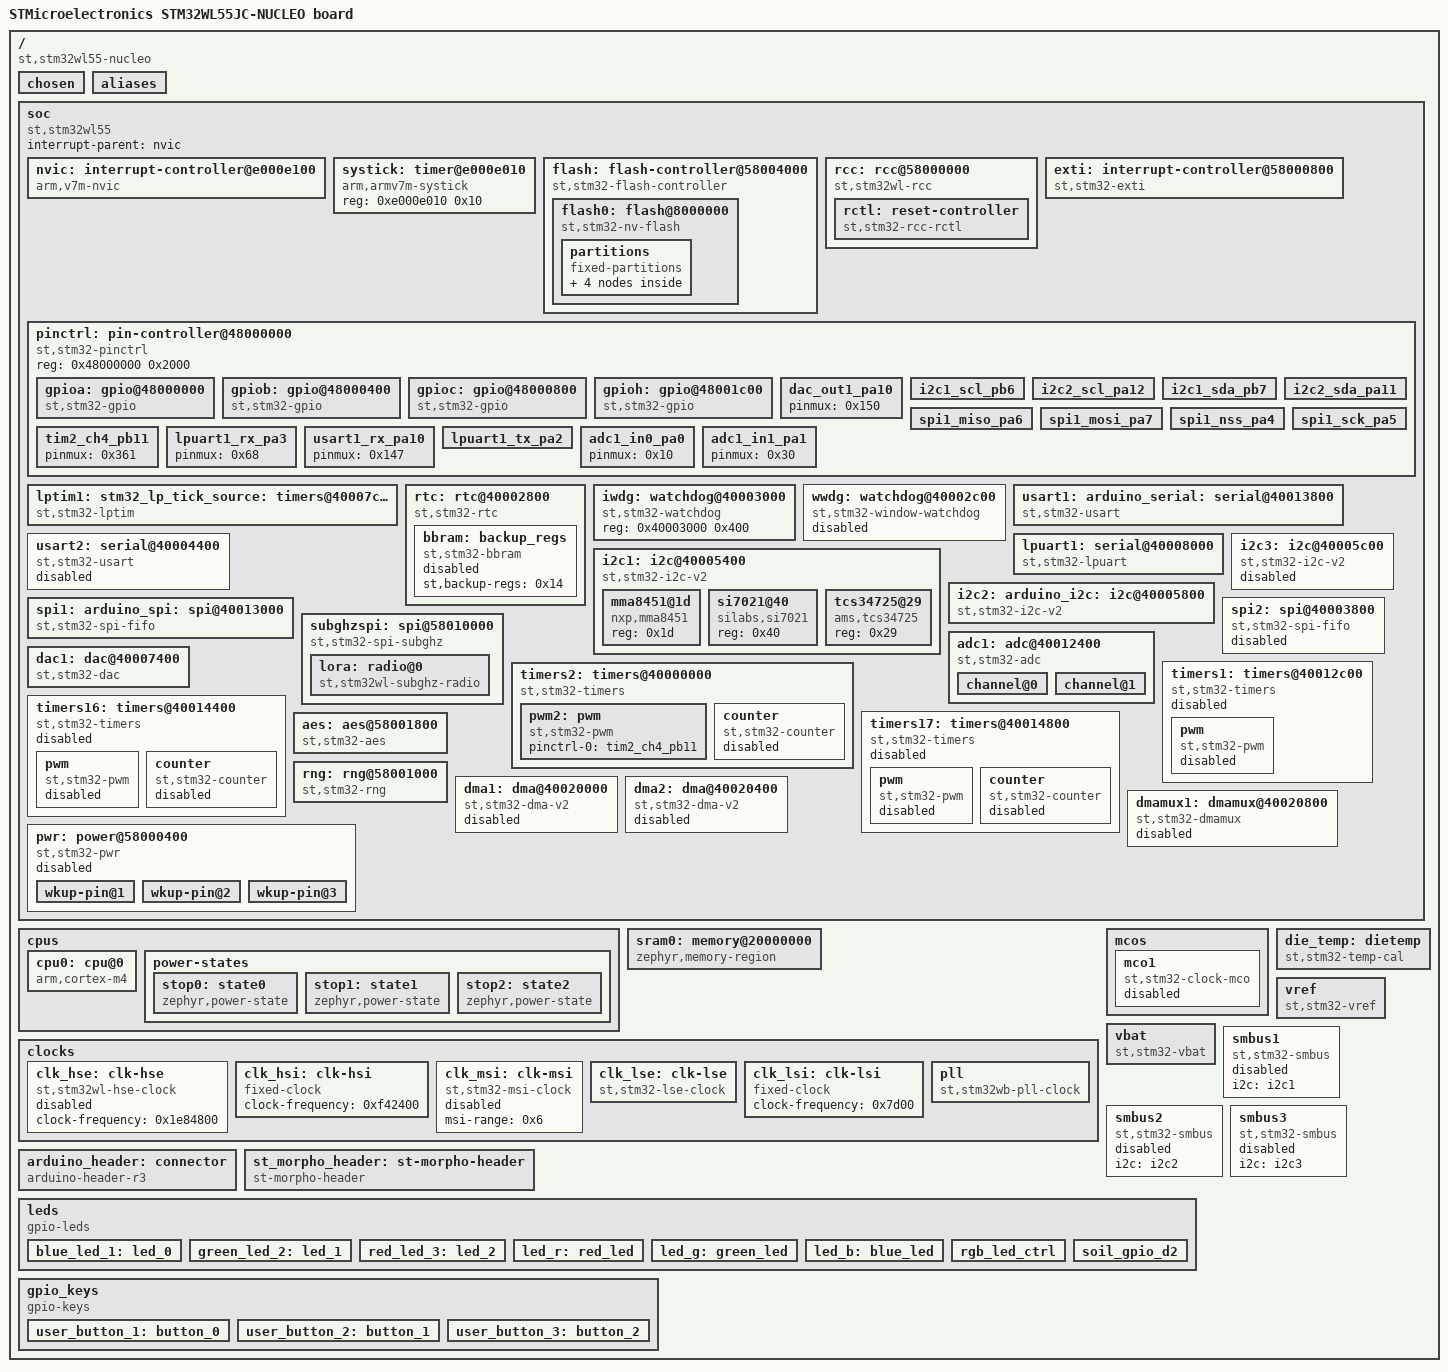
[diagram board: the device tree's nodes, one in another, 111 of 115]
/dts-v1/;

/* node '/' defined in zephyr\dts\common\skeleton.dtsi:9 */
/ {
	#address-cells = < 0x1 >;                              /* in zephyr\dts\common\skeleton.dtsi:10 */
	#size-cells = < 0x1 >;                                 /* in zephyr\dts\common\skeleton.dtsi:11 */
	model = "STMicroelectronics STM32WL55JC-NUCLEO board"; /* in zephyr\boards\st\nucleo_wl55jc\nucleo_wl55jc.dts:15 */
	compatible = "st,stm32wl55-nucleo";                    /* in zephyr\boards\st\nucleo_wl55jc\nucleo_wl55jc.dts:16 */

	/* node '/chosen' defined in zephyr\dts\common\skeleton.dtsi:13 */
	chosen {
		zephyr,entropy = &rng;                    /* in zephyr\dts\arm\st\wl\stm32wl.dtsi:24 */
		zephyr,flash-controller = &flash;         /* in zephyr\dts\arm\st\wl\stm32wl.dtsi:25 */
		zephyr,console = &lpuart1;                /* in zephyr\boards\st\nucleo_wl55jc\nucleo_wl55jc.dts:19 */
		zephyr,shell-uart = &lpuart1;             /* in zephyr\boards\st\nucleo_wl55jc\nucleo_wl55jc.dts:20 */
		zephyr,sram = &sram0;                     /* in zephyr\boards\st\nucleo_wl55jc\nucleo_wl55jc.dts:21 */
		zephyr,flash = &flash0;                   /* in zephyr\boards\st\nucleo_wl55jc\nucleo_wl55jc.dts:22 */
		zephyr,code-partition = &slot0_partition; /* in zephyr\boards\st\nucleo_wl55jc\nucleo_wl55jc.dts:23 */
	};

	/* node '/aliases' defined in zephyr\dts\common\skeleton.dtsi:15 */
	aliases {
		sw1 = &user_button_2;   /* in zephyr\boards\st\nucleo_wl55jc\nucleo_wl55jc.dts:77 */
		sw2 = &user_button_3;   /* in zephyr\boards\st\nucleo_wl55jc\nucleo_wl55jc.dts:78 */
		lora0 = &lora;          /* in zephyr\boards\st\nucleo_wl55jc\nucleo_wl55jc.dts:79 */
		watchdog0 = &iwdg;      /* in zephyr\boards\st\nucleo_wl55jc\nucleo_wl55jc.dts:80 */
		die-temp0 = &die_temp;  /* in zephyr\boards\st\nucleo_wl55jc\nucleo_wl55jc.dts:81 */
		volt-sensor0 = &vref;   /* in zephyr\boards\st\nucleo_wl55jc\nucleo_wl55jc.dts:82 */
		volt-sensor1 = &vbat;   /* in zephyr\boards\st\nucleo_wl55jc\nucleo_wl55jc.dts:83 */
		analogin0 = &adc1;      /* in ..\Downloads\blink_basic\build\zephyr\boards\nucleo_wl55jc.overlay:3 */
		led0 = &led_r;          /* in ..\Downloads\blink_basic\build\zephyr\boards\nucleo_wl55jc.overlay:4 */
		led1 = &led_g;          /* in ..\Downloads\blink_basic\build\zephyr\boards\nucleo_wl55jc.overlay:5 */
		led2 = &led_b;          /* in ..\Downloads\blink_basic\build\zephyr\boards\nucleo_wl55jc.overlay:6 */
		sw0 = &user_button_3;   /* in ..\Downloads\blink_basic\build\zephyr\boards\nucleo_wl55jc.overlay:7 */
		rgbled = &rgb_led_ctrl; /* in ..\Downloads\blink_basic\build\zephyr\boards\nucleo_wl55jc.overlay:8 */
		soil = &soil_gpio_d2;   /* in ..\Downloads\blink_basic\build\zephyr\boards\nucleo_wl55jc.overlay:9 */
	};

	/* node '/soc' defined in zephyr\dts\arm\armv7-m.dtsi:6 */
	soc {
		#address-cells = < 0x1 >;     /* in zephyr\dts\arm\armv7-m.dtsi:7 */
		#size-cells = < 0x1 >;        /* in zephyr\dts\arm\armv7-m.dtsi:8 */
		interrupt-parent = < &nvic >; /* in zephyr\dts\arm\armv7-m.dtsi:10 */
		ranges;                       /* in zephyr\dts\arm\armv7-m.dtsi:11 */
		compatible = "st,stm32wl55",
		             "st,stm32wl",
		             "simple-bus";    /* in zephyr\dts\arm\st\wl\stm32wl55.dtsi:11 */

		/* node '/soc/interrupt-controller@e000e100' defined in zephyr\dts\arm\armv7-m.dtsi:13 */
		nvic: interrupt-controller@e000e100 {
			#address-cells = < 0x1 >;            /* in zephyr\dts\arm\armv7-m.dtsi:14 */
			compatible = "arm,v7m-nvic";         /* in zephyr\dts\arm\armv7-m.dtsi:15 */
			reg = < 0xe000e100 0xc00 >;          /* in zephyr\dts\arm\armv7-m.dtsi:16 */
			interrupt-controller;                /* in zephyr\dts\arm\armv7-m.dtsi:17 */
			#interrupt-cells = < 0x2 >;          /* in zephyr\dts\arm\armv7-m.dtsi:18 */
			arm,num-irq-priority-bits = < 0x4 >; /* in zephyr\dts\arm\st\wl\stm32wl.dtsi:604 */
			phandle = < 0x1 >;                   /* in zephyr\dts\arm\armv7-m.dtsi:10 */
		};

		/* node '/soc/timer@e000e010' defined in zephyr\dts\arm\armv7-m.dtsi:21 */
		systick: timer@e000e010 {
			compatible = "arm,armv7m-systick"; /* in zephyr\dts\arm\armv7-m.dtsi:22 */
			reg = < 0xe000e010 0x10 >;         /* in zephyr\dts\arm\armv7-m.dtsi:23 */
		};

		/* node '/soc/flash-controller@58004000' defined in zephyr\dts\arm\st\wl\stm32wl.dtsi:121 */
		flash: flash-controller@58004000 {
			compatible = "st,stm32-flash-controller",
			             "st,stm32l4-flash-controller"; /* in zephyr\dts\arm\st\wl\stm32wl.dtsi:122 */
			reg = < 0x58004000 0x400 >;                 /* in zephyr\dts\arm\st\wl\stm32wl.dtsi:123 */
			interrupts = < 0x4 0x0 >;                   /* in zephyr\dts\arm\st\wl\stm32wl.dtsi:124 */
			#address-cells = < 0x1 >;                   /* in zephyr\dts\arm\st\wl\stm32wl.dtsi:126 */
			#size-cells = < 0x1 >;                      /* in zephyr\dts\arm\st\wl\stm32wl.dtsi:127 */

			/* node '/soc/flash-controller@58004000/flash@8000000' defined in zephyr\dts\arm\st\wl\stm32wl.dtsi:129 */
			flash0: flash@8000000 {
				compatible = "st,stm32-nv-flash",
				             "soc-nv-flash";      /* in zephyr\dts\arm\st\wl\stm32wl.dtsi:130 */
				write-block-size = < 0x8 >;       /* in zephyr\dts\arm\st\wl\stm32wl.dtsi:132 */
				erase-block-size = < 0x800 >;     /* in zephyr\dts\arm\st\wl\stm32wl.dtsi:133 */
				max-erase-time = < 0x19 >;        /* in zephyr\dts\arm\st\wl\stm32wl.dtsi:135 */
				reg = < 0x8000000 0x40000 >;      /* in zephyr\dts\arm\st\wl\stm32wl55Xc.dtsi:16 */

				/* node '/soc/flash-controller@58004000/flash@8000000/partitions' defined in zephyr\boards\st\nucleo_wl55jc\nucleo_wl55jc.dts:209 */
				partitions {
					compatible = "fixed-partitions"; /* in zephyr\boards\st\nucleo_wl55jc\nucleo_wl55jc.dts:210 */
					#address-cells = < 0x1 >;        /* in zephyr\boards\st\nucleo_wl55jc\nucleo_wl55jc.dts:211 */
					#size-cells = < 0x1 >;           /* in zephyr\boards\st\nucleo_wl55jc\nucleo_wl55jc.dts:212 */

					/* node '/soc/flash-controller@58004000/flash@8000000/partitions/partition@0' defined in zephyr\boards\st\nucleo_wl55jc\nucleo_wl55jc.dts:215 */
					boot_partition: partition@0 {
						label = "mcuboot";    /* in zephyr\boards\st\nucleo_wl55jc\nucleo_wl55jc.dts:216 */
						reg = < 0x0 0x8000 >; /* in zephyr\boards\st\nucleo_wl55jc\nucleo_wl55jc.dts:217 */
						read-only;            /* in zephyr\boards\st\nucleo_wl55jc\nucleo_wl55jc.dts:218 */
					};

					/* node '/soc/flash-controller@58004000/flash@8000000/partitions/partition@8000' defined in zephyr\boards\st\nucleo_wl55jc\nucleo_wl55jc.dts:222 */
					slot0_partition: partition@8000 {
						label = "image-0";        /* in zephyr\boards\st\nucleo_wl55jc\nucleo_wl55jc.dts:223 */
						reg = < 0x8000 0x1a000 >; /* in zephyr\boards\st\nucleo_wl55jc\nucleo_wl55jc.dts:224 */
					};

					/* node '/soc/flash-controller@58004000/flash@8000000/partitions/partition@22000' defined in zephyr\boards\st\nucleo_wl55jc\nucleo_wl55jc.dts:228 */
					slot1_partition: partition@22000 {
						label = "image-1";         /* in zephyr\boards\st\nucleo_wl55jc\nucleo_wl55jc.dts:229 */
						reg = < 0x22000 0x1a000 >; /* in zephyr\boards\st\nucleo_wl55jc\nucleo_wl55jc.dts:230 */
					};

					/* node '/soc/flash-controller@58004000/flash@8000000/partitions/partition@3c000' defined in zephyr\boards\st\nucleo_wl55jc\nucleo_wl55jc.dts:238 */
					storage_partition: partition@3c000 {
						label = "storage";        /* in zephyr\boards\st\nucleo_wl55jc\nucleo_wl55jc.dts:239 */
						reg = < 0x3c000 0x4000 >; /* in zephyr\boards\st\nucleo_wl55jc\nucleo_wl55jc.dts:240 */
					};
				};
			};
		};

		/* node '/soc/rcc@58000000' defined in zephyr\dts\arm\st\wl\stm32wl.dtsi:139 */
		rcc: rcc@58000000 {
			compatible = "st,stm32wl-rcc";   /* in zephyr\dts\arm\st\wl\stm32wl.dtsi:140 */
			#clock-cells = < 0x2 >;          /* in zephyr\dts\arm\st\wl\stm32wl.dtsi:141 */
			reg = < 0x58000000 0x400 >;      /* in zephyr\dts\arm\st\wl\stm32wl.dtsi:142 */
			clocks = < &pll >;               /* in zephyr\boards\st\nucleo_wl55jc\nucleo_wl55jc.dts:116 */
			clock-frequency = < 0x2dc6c00 >; /* in zephyr\boards\st\nucleo_wl55jc\nucleo_wl55jc.dts:117 */
			cpu1-prescaler = < 0x1 >;        /* in zephyr\boards\st\nucleo_wl55jc\nucleo_wl55jc.dts:118 */
			cpu2-prescaler = < 0x1 >;        /* in zephyr\boards\st\nucleo_wl55jc\nucleo_wl55jc.dts:119 */
			ahb3-prescaler = < 0x1 >;        /* in zephyr\boards\st\nucleo_wl55jc\nucleo_wl55jc.dts:120 */
			apb1-prescaler = < 0x1 >;        /* in zephyr\boards\st\nucleo_wl55jc\nucleo_wl55jc.dts:121 */
			apb2-prescaler = < 0x1 >;        /* in zephyr\boards\st\nucleo_wl55jc\nucleo_wl55jc.dts:122 */
			phandle = < 0x3 >;               /* in zephyr\dts\arm\st\wl\stm32wl.dtsi:156 */

			/* node '/soc/rcc@58000000/reset-controller' defined in zephyr\dts\arm\st\wl\stm32wl.dtsi:144 */
			rctl: reset-controller {
				compatible = "st,stm32-rcc-rctl"; /* in zephyr\dts\arm\st\wl\stm32wl.dtsi:145 */
				#reset-cells = < 0x1 >;           /* in zephyr\dts\arm\st\wl\stm32wl.dtsi:146 */
				phandle = < 0x4 >;                /* in zephyr\dts\arm\st\wl\stm32wl.dtsi:257 */
			};
		};

		/* node '/soc/interrupt-controller@58000800' defined in zephyr\dts\arm\st\wl\stm32wl.dtsi:150 */
		exti: interrupt-controller@58000800 {
			compatible = "st,stm32-exti";  /* in zephyr\dts\arm\st\wl\stm32wl.dtsi:151 */
			interrupt-controller;          /* in zephyr\dts\arm\st\wl\stm32wl.dtsi:152 */
			#interrupt-cells = < 0x1 >;    /* in zephyr\dts\arm\st\wl\stm32wl.dtsi:153 */
			#address-cells = < 0x0 >;      /* in zephyr\dts\arm\st\wl\stm32wl.dtsi:154 */
			reg = < 0x58000800 0x400 >;    /* in zephyr\dts\arm\st\wl\stm32wl.dtsi:155 */
			clocks = < &rcc 0x54 0x100 >;  /* in zephyr\dts\arm\st\wl\stm32wl.dtsi:156 */
			num-lines = < 0x40 >;          /* in zephyr\dts\arm\st\wl\stm32wl.dtsi:157 */
			interrupts = < 0x6 0x0 >,
			             < 0x7 0x0 >,
			             < 0x8 0x0 >,
			             < 0x9 0x0 >,
			             < 0xa 0x0 >,
			             < 0x16 0x0 >,
			             < 0x29 0x0 >;     /* in zephyr\dts\arm\st\wl\stm32wl.dtsi:158 */
			interrupt-names = "line0",
			                  "line1",
			                  "line2",
			                  "line3",
			                  "line4",
			                  "line5-9",
			                  "line10-15"; /* in zephyr\dts\arm\st\wl\stm32wl.dtsi:160 */
			line-ranges = < 0x0 0x1 >,
			              < 0x1 0x1 >,
			              < 0x2 0x1 >,
			              < 0x3 0x1 >,
			              < 0x4 0x1 >,
			              < 0x5 0x5 >,
			              < 0xa 0x6 >;     /* in zephyr\dts\arm\st\wl\stm32wl.dtsi:162 */
		};

		/* node '/soc/pin-controller@48000000' defined in zephyr\dts\arm\st\wl\stm32wl.dtsi:166 */
		pinctrl: pin-controller@48000000 {
			compatible = "st,stm32-pinctrl"; /* in zephyr\dts\arm\st\wl\stm32wl.dtsi:167 */
			#address-cells = < 0x1 >;        /* in zephyr\dts\arm\st\wl\stm32wl.dtsi:168 */
			#size-cells = < 0x1 >;           /* in zephyr\dts\arm\st\wl\stm32wl.dtsi:169 */
			reg = < 0x48000000 0x2000 >;     /* in zephyr\dts\arm\st\wl\stm32wl.dtsi:170 */

			/* node '/soc/pin-controller@48000000/gpio@48000000' defined in zephyr\dts\arm\st\wl\stm32wl.dtsi:172 */
			gpioa: gpio@48000000 {
				compatible = "st,stm32-gpio"; /* in zephyr\dts\arm\st\wl\stm32wl.dtsi:173 */
				gpio-controller;              /* in zephyr\dts\arm\st\wl\stm32wl.dtsi:174 */
				#gpio-cells = < 0x2 >;        /* in zephyr\dts\arm\st\wl\stm32wl.dtsi:175 */
				reg = < 0x48000000 0x400 >;   /* in zephyr\dts\arm\st\wl\stm32wl.dtsi:176 */
				clocks = < &rcc 0x4c 0x1 >;   /* in zephyr\dts\arm\st\wl\stm32wl.dtsi:177 */
				phandle = < 0x15 >;           /* in zephyr\dts\arm\st\wl\stm32wl.dtsi:537 */
			};

			/* node '/soc/pin-controller@48000000/gpio@48000400' defined in zephyr\dts\arm\st\wl\stm32wl.dtsi:180 */
			gpiob: gpio@48000400 {
				compatible = "st,stm32-gpio"; /* in zephyr\dts\arm\st\wl\stm32wl.dtsi:181 */
				gpio-controller;              /* in zephyr\dts\arm\st\wl\stm32wl.dtsi:182 */
				#gpio-cells = < 0x2 >;        /* in zephyr\dts\arm\st\wl\stm32wl.dtsi:183 */
				reg = < 0x48000400 0x400 >;   /* in zephyr\dts\arm\st\wl\stm32wl.dtsi:184 */
				clocks = < &rcc 0x4c 0x2 >;   /* in zephyr\dts\arm\st\wl\stm32wl.dtsi:185 */
				phandle = < 0x16 >;           /* in zephyr\dts\arm\st\wl\stm32wl.dtsi:547 */
			};

			/* node '/soc/pin-controller@48000000/gpio@48000800' defined in zephyr\dts\arm\st\wl\stm32wl.dtsi:188 */
			gpioc: gpio@48000800 {
				compatible = "st,stm32-gpio"; /* in zephyr\dts\arm\st\wl\stm32wl.dtsi:189 */
				gpio-controller;              /* in zephyr\dts\arm\st\wl\stm32wl.dtsi:190 */
				#gpio-cells = < 0x2 >;        /* in zephyr\dts\arm\st\wl\stm32wl.dtsi:191 */
				reg = < 0x48000800 0x400 >;   /* in zephyr\dts\arm\st\wl\stm32wl.dtsi:192 */
				clocks = < &rcc 0x4c 0x4 >;   /* in zephyr\dts\arm\st\wl\stm32wl.dtsi:193 */
				phandle = < 0x10 >;           /* in zephyr\boards\st\nucleo_wl55jc\nucleo_wl55jc.dts:193 */
			};

			/* node '/soc/pin-controller@48000000/gpio@48001c00' defined in zephyr\dts\arm\st\wl\stm32wl.dtsi:196 */
			gpioh: gpio@48001c00 {
				compatible = "st,stm32-gpio"; /* in zephyr\dts\arm\st\wl\stm32wl.dtsi:197 */
				gpio-controller;              /* in zephyr\dts\arm\st\wl\stm32wl.dtsi:198 */
				#gpio-cells = < 0x2 >;        /* in zephyr\dts\arm\st\wl\stm32wl.dtsi:199 */
				reg = < 0x48001c00 0x400 >;   /* in zephyr\dts\arm\st\wl\stm32wl.dtsi:200 */
				clocks = < &rcc 0x4c 0x80 >;  /* in zephyr\dts\arm\st\wl\stm32wl.dtsi:201 */
				phandle = < 0x1f >;           /* in zephyr\boards\st\nucleo_wl55jc\st_morpho_connector.dtsi:15 */
			};

			/* node '/soc/pin-controller@48000000/dac_out1_pa10' defined in modules\hal\stm32\dts\st\wl\stm32wl55jcix-pinctrl.dtsi:323 */
			dac_out1_pa10: dac_out1_pa10 {
				pinmux = < 0x150 >; /* in modules\hal\stm32\dts\st\wl\stm32wl55jcix-pinctrl.dtsi:324 */
				phandle = < 0x13 >; /* in zephyr\boards\st\nucleo_wl55jc\nucleo_wl55jc.dts:147 */
			};

			/* node '/soc/pin-controller@48000000/i2c1_scl_pb6' defined in modules\hal\stm32\dts\st\wl\stm32wl55jcix-pinctrl.dtsi:335 */
			i2c1_scl_pb6: i2c1_scl_pb6 {
				pinmux = < 0x2c4 >; /* in modules\hal\stm32\dts\st\wl\stm32wl55jcix-pinctrl.dtsi:336 */
				bias-pull-up;       /* in modules\hal\stm32\dts\st\wl\stm32wl55jcix-pinctrl.dtsi:337 */
				drive-open-drain;   /* in modules\hal\stm32\dts\st\wl\stm32wl55jcix-pinctrl.dtsi:338 */
				phandle = < 0x8 >;  /* in ..\Downloads\blink_basic\build\zephyr\boards\nucleo_wl55jc.overlay:69 */
			};

			/* node '/soc/pin-controller@48000000/i2c2_scl_pa12' defined in modules\hal\stm32\dts\st\wl\stm32wl55jcix-pinctrl.dtsi:347 */
			i2c2_scl_pa12: i2c2_scl_pa12 {
				pinmux = < 0x184 >; /* in modules\hal\stm32\dts\st\wl\stm32wl55jcix-pinctrl.dtsi:348 */
				bias-pull-up;       /* in modules\hal\stm32\dts\st\wl\stm32wl55jcix-pinctrl.dtsi:349 */
				drive-open-drain;   /* in modules\hal\stm32\dts\st\wl\stm32wl55jcix-pinctrl.dtsi:350 */
				phandle = < 0xa >;  /* in zephyr\boards\st\nucleo_wl55jc\nucleo_wl55jc.dts:133 */
			};

			/* node '/soc/pin-controller@48000000/i2c1_sda_pb7' defined in modules\hal\stm32\dts\st\wl\stm32wl55jcix-pinctrl.dtsi:391 */
			i2c1_sda_pb7: i2c1_sda_pb7 {
				pinmux = < 0x2e4 >; /* in modules\hal\stm32\dts\st\wl\stm32wl55jcix-pinctrl.dtsi:392 */
				bias-pull-up;       /* in modules\hal\stm32\dts\st\wl\stm32wl55jcix-pinctrl.dtsi:393 */
				drive-open-drain;   /* in modules\hal\stm32\dts\st\wl\stm32wl55jcix-pinctrl.dtsi:394 */
				phandle = < 0x9 >;  /* in ..\Downloads\blink_basic\build\zephyr\boards\nucleo_wl55jc.overlay:69 */
			};

			/* node '/soc/pin-controller@48000000/i2c2_sda_pa11' defined in modules\hal\stm32\dts\st\wl\stm32wl55jcix-pinctrl.dtsi:403 */
			i2c2_sda_pa11: i2c2_sda_pa11 {
				pinmux = < 0x164 >; /* in modules\hal\stm32\dts\st\wl\stm32wl55jcix-pinctrl.dtsi:404 */
				bias-pull-up;       /* in modules\hal\stm32\dts\st\wl\stm32wl55jcix-pinctrl.dtsi:405 */
				drive-open-drain;   /* in modules\hal\stm32\dts\st\wl\stm32wl55jcix-pinctrl.dtsi:406 */
				phandle = < 0xb >;  /* in zephyr\boards\st\nucleo_wl55jc\nucleo_wl55jc.dts:133 */
			};

			/* node '/soc/pin-controller@48000000/spi1_miso_pa6' defined in modules\hal\stm32\dts\st\wl\stm32wl55jcix-pinctrl.dtsi:583 */
			spi1_miso_pa6: spi1_miso_pa6 {
				pinmux = < 0xc5 >; /* in modules\hal\stm32\dts\st\wl\stm32wl55jcix-pinctrl.dtsi:584 */
				bias-pull-down;    /* in modules\hal\stm32\dts\st\wl\stm32wl55jcix-pinctrl.dtsi:585 */
				phandle = < 0xe >; /* in zephyr\boards\st\nucleo_wl55jc\nucleo_wl55jc.dts:140 */
			};

			/* node '/soc/pin-controller@48000000/spi1_mosi_pa7' defined in modules\hal\stm32\dts\st\wl\stm32wl55jcix-pinctrl.dtsi:615 */
			spi1_mosi_pa7: spi1_mosi_pa7 {
				pinmux = < 0xe5 >; /* in modules\hal\stm32\dts\st\wl\stm32wl55jcix-pinctrl.dtsi:616 */
				bias-pull-down;    /* in modules\hal\stm32\dts\st\wl\stm32wl55jcix-pinctrl.dtsi:617 */
				phandle = < 0xf >; /* in zephyr\boards\st\nucleo_wl55jc\nucleo_wl55jc.dts:140 */
			};

			/* node '/soc/pin-controller@48000000/spi1_nss_pa4' defined in modules\hal\stm32\dts\st\wl\stm32wl55jcix-pinctrl.dtsi:652 */
			spi1_nss_pa4: spi1_nss_pa4 {
				pinmux = < 0x85 >; /* in modules\hal\stm32\dts\st\wl\stm32wl55jcix-pinctrl.dtsi:653 */
				bias-pull-up;      /* in modules\hal\stm32\dts\st\wl\stm32wl55jcix-pinctrl.dtsi:654 */
				phandle = < 0xc >; /* in zephyr\boards\st\nucleo_wl55jc\nucleo_wl55jc.dts:140 */
			};

			/* node '/soc/pin-controller@48000000/spi1_sck_pa5' defined in modules\hal\stm32\dts\st\wl\stm32wl55jcix-pinctrl.dtsi:690 */
			spi1_sck_pa5: spi1_sck_pa5 {
				pinmux = < 0xa5 >;             /* in modules\hal\stm32\dts\st\wl\stm32wl55jcix-pinctrl.dtsi:691 */
				bias-pull-down;                /* in modules\hal\stm32\dts\st\wl\stm32wl55jcix-pinctrl.dtsi:692 */
				slew-rate = "very-high-speed"; /* in modules\hal\stm32\dts\st\wl\stm32wl55jcix-pinctrl.dtsi:693 */
				phandle = < 0xd >;             /* in zephyr\boards\st\nucleo_wl55jc\nucleo_wl55jc.dts:140 */
			};

			/* node '/soc/pin-controller@48000000/tim2_ch4_pb11' defined in modules\hal\stm32\dts\st\wl\stm32wl55jcix-pinctrl.dtsi:830 */
			tim2_ch4_pb11: tim2_ch4_pb11 {
				pinmux = < 0x361 >; /* in modules\hal\stm32\dts\st\wl\stm32wl55jcix-pinctrl.dtsi:831 */
				phandle = < 0x14 >; /* in zephyr\boards\st\nucleo_wl55jc\nucleo_wl55jc.dts:158 */
			};

			/* node '/soc/pin-controller@48000000/lpuart1_rx_pa3' defined in modules\hal\stm32\dts\st\wl\stm32wl55jcix-pinctrl.dtsi:941 */
			lpuart1_rx_pa3: lpuart1_rx_pa3 {
				pinmux = < 0x68 >; /* in modules\hal\stm32\dts\st\wl\stm32wl55jcix-pinctrl.dtsi:942 */
				phandle = < 0x7 >; /* in zephyr\boards\st\nucleo_wl55jc\nucleo_wl55jc.dts:126 */
			};

			/* node '/soc/pin-controller@48000000/usart1_rx_pa10' defined in modules\hal\stm32\dts\st\wl\stm32wl55jcix-pinctrl.dtsi:945 */
			usart1_rx_pa10: usart1_rx_pa10 {
				pinmux = < 0x147 >; /* in modules\hal\stm32\dts\st\wl\stm32wl55jcix-pinctrl.dtsi:946 */
				phandle = < 0x5 >;  /* in ..\Downloads\blink_basic\build\zephyr\boards\nucleo_wl55jc.overlay:111 */
			};

			/* node '/soc/pin-controller@48000000/lpuart1_tx_pa2' defined in modules\hal\stm32\dts\st\wl\stm32wl55jcix-pinctrl.dtsi:967 */
			lpuart1_tx_pa2: lpuart1_tx_pa2 {
				pinmux = < 0x48 >; /* in modules\hal\stm32\dts\st\wl\stm32wl55jcix-pinctrl.dtsi:968 */
				bias-pull-up;      /* in modules\hal\stm32\dts\st\wl\stm32wl55jcix-pinctrl.dtsi:969 */
				phandle = < 0x6 >; /* in zephyr\boards\st\nucleo_wl55jc\nucleo_wl55jc.dts:126 */
			};

			/* node '/soc/pin-controller@48000000/adc1_in0_pa0' defined in ..\Downloads\blink_basic\build\zephyr\boards\nucleo_wl55jc.overlay:100 */
			adc1_in0_pa0: adc1_in0_pa0 {
				pinmux = < 0x10 >;  /* in ..\Downloads\blink_basic\build\zephyr\boards\nucleo_wl55jc.overlay:101 */
				phandle = < 0x11 >; /* in ..\Downloads\blink_basic\build\zephyr\boards\nucleo_wl55jc.overlay:44 */
			};

			/* node '/soc/pin-controller@48000000/adc1_in1_pa1' defined in ..\Downloads\blink_basic\build\zephyr\boards\nucleo_wl55jc.overlay:103 */
			adc1_in1_pa1: adc1_in1_pa1 {
				pinmux = < 0x30 >;  /* in ..\Downloads\blink_basic\build\zephyr\boards\nucleo_wl55jc.overlay:104 */
				phandle = < 0x12 >; /* in ..\Downloads\blink_basic\build\zephyr\boards\nucleo_wl55jc.overlay:44 */
			};
		};

		/* node '/soc/timers@40007c00' defined in zephyr\dts\arm\st\wl\stm32wl.dtsi:205 */
		lptim1: stm32_lp_tick_source: timers@40007c00 {
			compatible = "st,stm32-lptim";     /* in zephyr\dts\arm\st\wl\stm32wl.dtsi:206 */
			#address-cells = < 0x1 >;          /* in zephyr\dts\arm\st\wl\stm32wl.dtsi:208 */
			#size-cells = < 0x0 >;             /* in zephyr\dts\arm\st\wl\stm32wl.dtsi:209 */
			reg = < 0x40007c00 0x400 >;        /* in zephyr\dts\arm\st\wl\stm32wl.dtsi:210 */
			interrupts = < 0x27 0x1 >;         /* in zephyr\dts\arm\st\wl\stm32wl.dtsi:211 */
			interrupt-names = "wakeup";        /* in zephyr\dts\arm\st\wl\stm32wl.dtsi:212 */
			clocks = < &rcc 0x58 0x80000000 >,
			         < &rcc 0x3 0x1320088 >;   /* in zephyr\boards\st\nucleo_wl55jc\nucleo_wl55jc.dts:93 */
			status = "okay";                   /* in zephyr\boards\st\nucleo_wl55jc\nucleo_wl55jc.dts:95 */
		};

		/* node '/soc/rtc@40002800' defined in zephyr\dts\arm\st\wl\stm32wl.dtsi:216 */
		rtc: rtc@40002800 {
			compatible = "st,stm32-rtc";     /* in zephyr\dts\arm\st\wl\stm32wl.dtsi:217 */
			reg = < 0x40002800 0x400 >;      /* in zephyr\dts\arm\st\wl\stm32wl.dtsi:218 */
			interrupts = < 0x2a 0x0 >;       /* in zephyr\dts\arm\st\wl\stm32wl.dtsi:219 */
			prescaler = < 0x8000 >;          /* in zephyr\dts\arm\st\wl\stm32wl.dtsi:221 */
			alarms-count = < 0x2 >;          /* in zephyr\dts\arm\st\wl\stm32wl.dtsi:222 */
			alrm-exti-line = < 0x11 >;       /* in zephyr\dts\arm\st\wl\stm32wl.dtsi:223 */
			clocks = < &rcc 0x58 0x400 >,
			         < &rcc 0x2 0x1280090 >; /* in zephyr\boards\st\nucleo_wl55jc\nucleo_wl55jc.dts:246 */
			status = "okay";                 /* in zephyr\boards\st\nucleo_wl55jc\nucleo_wl55jc.dts:248 */

			/* node '/soc/rtc@40002800/backup_regs' defined in zephyr\dts\arm\st\wl\stm32wl.dtsi:232 */
			bbram: backup_regs {
				compatible = "st,stm32-bbram"; /* in zephyr\dts\arm\st\wl\stm32wl.dtsi:233 */
				st,backup-regs = < 0x14 >;     /* in zephyr\dts\arm\st\wl\stm32wl.dtsi:234 */
				status = "disabled";           /* in zephyr\dts\arm\st\wl\stm32wl.dtsi:235 */
			};
		};

		/* node '/soc/watchdog@40003000' defined in zephyr\dts\arm\st\wl\stm32wl.dtsi:239 */
		iwdg: watchdog@40003000 {
			compatible = "st,stm32-watchdog"; /* in zephyr\dts\arm\st\wl\stm32wl.dtsi:240 */
			reg = < 0x40003000 0x400 >;       /* in zephyr\dts\arm\st\wl\stm32wl.dtsi:241 */
			status = "okay";                  /* in zephyr\boards\st\nucleo_wl55jc\nucleo_wl55jc.dts:184 */
		};

		/* node '/soc/watchdog@40002c00' defined in zephyr\dts\arm\st\wl\stm32wl.dtsi:245 */
		wwdg: watchdog@40002c00 {
			compatible = "st,stm32-window-watchdog"; /* in zephyr\dts\arm\st\wl\stm32wl.dtsi:246 */
			reg = < 0x40002c00 0x400 >;              /* in zephyr\dts\arm\st\wl\stm32wl.dtsi:247 */
			clocks = < &rcc 0x58 0x800 >;            /* in zephyr\dts\arm\st\wl\stm32wl.dtsi:248 */
			interrupts = < 0x0 0x7 >;                /* in zephyr\dts\arm\st\wl\stm32wl.dtsi:249 */
			status = "disabled";                     /* in zephyr\dts\arm\st\wl\stm32wl.dtsi:250 */
		};

		/* node '/soc/serial@40013800' defined in zephyr\dts\arm\st\wl\stm32wl.dtsi:253 */
		usart1: arduino_serial: serial@40013800 {
			compatible = "st,stm32-usart",
			             "st,stm32-uart";    /* in zephyr\dts\arm\st\wl\stm32wl.dtsi:254 */
			reg = < 0x40013800 0x400 >;      /* in zephyr\dts\arm\st\wl\stm32wl.dtsi:255 */
			clocks = < &rcc 0x60 0x4000 >;   /* in zephyr\dts\arm\st\wl\stm32wl.dtsi:256 */
			resets = < &rctl 0x80e >;        /* in zephyr\dts\arm\st\wl\stm32wl.dtsi:257 */
			interrupts = < 0x24 0x0 >;       /* in zephyr\dts\arm\st\wl\stm32wl.dtsi:258 */
			status = "okay";                 /* in ..\Downloads\blink_basic\build\zephyr\boards\nucleo_wl55jc.overlay:109 */
			current-speed = < 0x2580 >;      /* in ..\Downloads\blink_basic\build\zephyr\boards\nucleo_wl55jc.overlay:110 */
			pinctrl-0 = < &usart1_rx_pa10 >; /* in ..\Downloads\blink_basic\build\zephyr\boards\nucleo_wl55jc.overlay:111 */
			pinctrl-names = "default";       /* in ..\Downloads\blink_basic\build\zephyr\boards\nucleo_wl55jc.overlay:112 */
		};

		/* node '/soc/serial@40004400' defined in zephyr\dts\arm\st\wl\stm32wl.dtsi:262 */
		usart2: serial@40004400 {
			compatible = "st,stm32-usart",
			             "st,stm32-uart";   /* in zephyr\dts\arm\st\wl\stm32wl.dtsi:263 */
			reg = < 0x40004400 0x400 >;     /* in zephyr\dts\arm\st\wl\stm32wl.dtsi:264 */
			clocks = < &rcc 0x58 0x20000 >; /* in zephyr\dts\arm\st\wl\stm32wl.dtsi:265 */
			resets = < &rctl 0x711 >;       /* in zephyr\dts\arm\st\wl\stm32wl.dtsi:266 */
			interrupts = < 0x25 0x0 >;      /* in zephyr\dts\arm\st\wl\stm32wl.dtsi:267 */
			status = "disabled";            /* in zephyr\dts\arm\st\wl\stm32wl.dtsi:268 */
		};

		/* node '/soc/serial@40008000' defined in zephyr\dts\arm\st\wl\stm32wl.dtsi:271 */
		lpuart1: serial@40008000 {
			compatible = "st,stm32-lpuart",
			             "st,stm32-uart";                    /* in zephyr\dts\arm\st\wl\stm32wl.dtsi:272 */
			reg = < 0x40008000 0x400 >;                      /* in zephyr\dts\arm\st\wl\stm32wl.dtsi:273 */
			clocks = < &rcc 0x5c 0x1 >;                      /* in zephyr\dts\arm\st\wl\stm32wl.dtsi:274 */
			resets = < &rctl 0x780 >;                        /* in zephyr\dts\arm\st\wl\stm32wl.dtsi:275 */
			interrupts = < 0x26 0x0 >;                       /* in zephyr\dts\arm\st\wl\stm32wl.dtsi:276 */
			wakeup-line = < 0x1c >;                          /* in zephyr\dts\arm\st\wl\stm32wl.dtsi:277 */
			pinctrl-0 = < &lpuart1_tx_pa2 &lpuart1_rx_pa3 >; /* in zephyr\boards\st\nucleo_wl55jc\nucleo_wl55jc.dts:126 */
			pinctrl-names = "default";                       /* in zephyr\boards\st\nucleo_wl55jc\nucleo_wl55jc.dts:127 */
			current-speed = < 0x1c200 >;                     /* in zephyr\boards\st\nucleo_wl55jc\nucleo_wl55jc.dts:128 */
			status = "okay";                                 /* in zephyr\boards\st\nucleo_wl55jc\nucleo_wl55jc.dts:129 */
		};

		/* node '/soc/i2c@40005400' defined in zephyr\dts\arm\st\wl\stm32wl.dtsi:281 */
		i2c1: i2c@40005400 {
			compatible = "st,stm32-i2c-v2";              /* in zephyr\dts\arm\st\wl\stm32wl.dtsi:282 */
			#address-cells = < 0x1 >;                    /* in zephyr\dts\arm\st\wl\stm32wl.dtsi:284 */
			#size-cells = < 0x0 >;                       /* in zephyr\dts\arm\st\wl\stm32wl.dtsi:285 */
			reg = < 0x40005400 0x400 >;                  /* in zephyr\dts\arm\st\wl\stm32wl.dtsi:286 */
			clocks = < &rcc 0x58 0x200000 >;             /* in zephyr\dts\arm\st\wl\stm32wl.dtsi:287 */
			interrupts = < 0x1e 0x0 >,
			             < 0x1f 0x0 >;                   /* in zephyr\dts\arm\st\wl\stm32wl.dtsi:288 */
			interrupt-names = "event",
			                  "error";                   /* in zephyr\dts\arm\st\wl\stm32wl.dtsi:289 */
			status = "okay";                             /* in ..\Downloads\blink_basic\build\zephyr\boards\nucleo_wl55jc.overlay:67 */
			clock-frequency = < 0x61a80 >;               /* in ..\Downloads\blink_basic\build\zephyr\boards\nucleo_wl55jc.overlay:68 */
			pinctrl-0 = < &i2c1_scl_pb6 &i2c1_sda_pb7 >; /* in ..\Downloads\blink_basic\build\zephyr\boards\nucleo_wl55jc.overlay:69 */
			pinctrl-names = "default";                   /* in ..\Downloads\blink_basic\build\zephyr\boards\nucleo_wl55jc.overlay:70 */
			phandle = < 0x1c >;                          /* in zephyr\dts\arm\st\wl\stm32wl.dtsi:582 */

			/* node '/soc/i2c@40005400/mma8451@1d' defined in ..\Downloads\blink_basic\build\zephyr\boards\nucleo_wl55jc.overlay:72 */
			mma8451@1d {
				compatible = "nxp,mma8451"; /* in ..\Downloads\blink_basic\build\zephyr\boards\nucleo_wl55jc.overlay:73 */
				reg = < 0x1d >;             /* in ..\Downloads\blink_basic\build\zephyr\boards\nucleo_wl55jc.overlay:74 */
				status = "okay";            /* in ..\Downloads\blink_basic\build\zephyr\boards\nucleo_wl55jc.overlay:75 */
			};

			/* node '/soc/i2c@40005400/si7021@40' defined in ..\Downloads\blink_basic\build\zephyr\boards\nucleo_wl55jc.overlay:78 */
			si7021@40 {
				compatible = "silabs,si7021"; /* in ..\Downloads\blink_basic\build\zephyr\boards\nucleo_wl55jc.overlay:79 */
				reg = < 0x40 >;               /* in ..\Downloads\blink_basic\build\zephyr\boards\nucleo_wl55jc.overlay:80 */
				status = "okay";              /* in ..\Downloads\blink_basic\build\zephyr\boards\nucleo_wl55jc.overlay:81 */
			};

			/* node '/soc/i2c@40005400/tcs34725@29' defined in ..\Downloads\blink_basic\build\zephyr\boards\nucleo_wl55jc.overlay:84 */
			tcs34725@29 {
				compatible = "ams,tcs34725"; /* in ..\Downloads\blink_basic\build\zephyr\boards\nucleo_wl55jc.overlay:85 */
				reg = < 0x29 >;              /* in ..\Downloads\blink_basic\build\zephyr\boards\nucleo_wl55jc.overlay:86 */
				status = "okay";             /* in ..\Downloads\blink_basic\build\zephyr\boards\nucleo_wl55jc.overlay:87 */
			};
		};

		/* node '/soc/i2c@40005800' defined in zephyr\dts\arm\st\wl\stm32wl.dtsi:293 */
		i2c2: arduino_i2c: i2c@40005800 {
			compatible = "st,stm32-i2c-v2";                /* in zephyr\dts\arm\st\wl\stm32wl.dtsi:294 */
			#address-cells = < 0x1 >;                      /* in zephyr\dts\arm\st\wl\stm32wl.dtsi:296 */
			#size-cells = < 0x0 >;                         /* in zephyr\dts\arm\st\wl\stm32wl.dtsi:297 */
			reg = < 0x40005800 0x400 >;                    /* in zephyr\dts\arm\st\wl\stm32wl.dtsi:298 */
			clocks = < &rcc 0x58 0x400000 >;               /* in zephyr\dts\arm\st\wl\stm32wl.dtsi:299 */
			interrupts = < 0x20 0x0 >,
			             < 0x21 0x0 >;                     /* in zephyr\dts\arm\st\wl\stm32wl.dtsi:300 */
			interrupt-names = "event",
			                  "error";                     /* in zephyr\dts\arm\st\wl\stm32wl.dtsi:301 */
			pinctrl-0 = < &i2c2_scl_pa12 &i2c2_sda_pa11 >; /* in zephyr\boards\st\nucleo_wl55jc\nucleo_wl55jc.dts:133 */
			pinctrl-names = "default";                     /* in zephyr\boards\st\nucleo_wl55jc\nucleo_wl55jc.dts:134 */
			status = "okay";                               /* in zephyr\boards\st\nucleo_wl55jc\nucleo_wl55jc.dts:135 */
			clock-frequency = < 0x61a80 >;                 /* in zephyr\boards\st\nucleo_wl55jc\nucleo_wl55jc.dts:136 */
			phandle = < 0x1d >;                            /* in zephyr\dts\arm\st\wl\stm32wl.dtsi:590 */
		};

		/* node '/soc/i2c@40005c00' defined in zephyr\dts\arm\st\wl\stm32wl.dtsi:305 */
		i2c3: i2c@40005c00 {
			compatible = "st,stm32-i2c-v2";  /* in zephyr\dts\arm\st\wl\stm32wl.dtsi:306 */
			clock-frequency = < 0x186a0 >;   /* in zephyr\dts\arm\st\wl\stm32wl.dtsi:307 */
			#address-cells = < 0x1 >;        /* in zephyr\dts\arm\st\wl\stm32wl.dtsi:308 */
			#size-cells = < 0x0 >;           /* in zephyr\dts\arm\st\wl\stm32wl.dtsi:309 */
			reg = < 0x40005c00 0x400 >;      /* in zephyr\dts\arm\st\wl\stm32wl.dtsi:310 */
			clocks = < &rcc 0x58 0x800000 >; /* in zephyr\dts\arm\st\wl\stm32wl.dtsi:311 */
			interrupts = < 0x30 0x0 >,
			             < 0x31 0x0 >;       /* in zephyr\dts\arm\st\wl\stm32wl.dtsi:312 */
			interrupt-names = "event",
			                  "error";       /* in zephyr\dts\arm\st\wl\stm32wl.dtsi:313 */
			status = "disabled";             /* in zephyr\dts\arm\st\wl\stm32wl.dtsi:314 */
			phandle = < 0x1e >;              /* in zephyr\dts\arm\st\wl\stm32wl.dtsi:598 */
		};

		/* node '/soc/spi@40013000' defined in zephyr\dts\arm\st\wl\stm32wl.dtsi:317 */
		spi1: arduino_spi: spi@40013000 {
			compatible = "st,stm32-spi-fifo",
			             "st,stm32-spi";                                               /* in zephyr\dts\arm\st\wl\stm32wl.dtsi:318 */
			#address-cells = < 0x1 >;                                                  /* in zephyr\dts\arm\st\wl\stm32wl.dtsi:319 */
			#size-cells = < 0x0 >;                                                     /* in zephyr\dts\arm\st\wl\stm32wl.dtsi:320 */
			reg = < 0x40013000 0x400 >;                                                /* in zephyr\dts\arm\st\wl\stm32wl.dtsi:321 */
			interrupts = < 0x22 0x5 >;                                                 /* in zephyr\dts\arm\st\wl\stm32wl.dtsi:322 */
			clocks = < &rcc 0x60 0x1000 >;                                             /* in zephyr\dts\arm\st\wl\stm32wl.dtsi:323 */
			pinctrl-0 = < &spi1_nss_pa4 &spi1_sck_pa5 &spi1_miso_pa6 &spi1_mosi_pa7 >; /* in zephyr\boards\st\nucleo_wl55jc\nucleo_wl55jc.dts:140 */
			pinctrl-names = "default";                                                 /* in zephyr\boards\st\nucleo_wl55jc\nucleo_wl55jc.dts:142 */
			status = "okay";                                                           /* in zephyr\boards\st\nucleo_wl55jc\nucleo_wl55jc.dts:143 */
		};

		/* node '/soc/spi@40003800' defined in zephyr\dts\arm\st\wl\stm32wl.dtsi:327 */
		spi2: spi@40003800 {
			compatible = "st,stm32-spi-fifo",
			             "st,stm32-spi";      /* in zephyr\dts\arm\st\wl\stm32wl.dtsi:328 */
			#address-cells = < 0x1 >;         /* in zephyr\dts\arm\st\wl\stm32wl.dtsi:329 */
			#size-cells = < 0x0 >;            /* in zephyr\dts\arm\st\wl\stm32wl.dtsi:330 */
			reg = < 0x40003800 0x400 >;       /* in zephyr\dts\arm\st\wl\stm32wl.dtsi:331 */
			interrupts = < 0x23 0x5 >;        /* in zephyr\dts\arm\st\wl\stm32wl.dtsi:332 */
			clocks = < &rcc 0x58 0x4000 >;    /* in zephyr\dts\arm\st\wl\stm32wl.dtsi:333 */
			status = "disabled";              /* in zephyr\dts\arm\st\wl\stm32wl.dtsi:334 */
		};

		/* node '/soc/spi@58010000' defined in zephyr\dts\arm\st\wl\stm32wl.dtsi:337 */
		subghzspi: spi@58010000 {
			compatible = "st,stm32-spi-subghz",
			             "st,stm32-spi-fifo",
			             "st,stm32-spi";        /* in zephyr\dts\arm\st\wl\stm32wl.dtsi:338 */
			#address-cells = < 0x1 >;           /* in zephyr\dts\arm\st\wl\stm32wl.dtsi:339 */
			#size-cells = < 0x0 >;              /* in zephyr\dts\arm\st\wl\stm32wl.dtsi:340 */
			reg = < 0x58010000 0x400 >;         /* in zephyr\dts\arm\st\wl\stm32wl.dtsi:341 */
			interrupts = < 0x2c 0x5 >;          /* in zephyr\dts\arm\st\wl\stm32wl.dtsi:342 */
			clocks = < &rcc 0x64 0x1 >;         /* in zephyr\dts\arm\st\wl\stm32wl.dtsi:343 */
			use-subghzspi-nss;                  /* in zephyr\dts\arm\st\wl\stm32wl.dtsi:345 */
			status = "okay";                    /* in zephyr\boards\st\nucleo_wl55jc\nucleo_wl55jc.dts:188 */

			/* node '/soc/spi@58010000/radio@0' defined in zephyr\dts\arm\st\wl\stm32wl.dtsi:347 */
			lora: radio@0 {
				compatible = "st,stm32wl-subghz-radio"; /* in zephyr\dts\arm\st\wl\stm32wl.dtsi:348 */
				reg = < 0x0 >;                          /* in zephyr\dts\arm\st\wl\stm32wl.dtsi:349 */
				interrupts = < 0x32 0x0 >;              /* in zephyr\dts\arm\st\wl\stm32wl.dtsi:350 */
				spi-max-frequency = < 0x7a1200 >;       /* in zephyr\dts\arm\st\wl\stm32wl.dtsi:351 */
				status = "okay";                        /* in zephyr\boards\st\nucleo_wl55jc\nucleo_wl55jc.dts:192 */
				tx-enable-gpios = < &gpioc 0x4 0x1 >;   /* in zephyr\boards\st\nucleo_wl55jc\nucleo_wl55jc.dts:193 */
				rx-enable-gpios = < &gpioc 0x5 0x1 >;   /* in zephyr\boards\st\nucleo_wl55jc\nucleo_wl55jc.dts:194 */
				dio3-tcxo-voltage = < 0x1 >;            /* in zephyr\boards\st\nucleo_wl55jc\nucleo_wl55jc.dts:195 */
				tcxo-power-startup-delay-ms = < 0x5 >;  /* in zephyr\boards\st\nucleo_wl55jc\nucleo_wl55jc.dts:196 */
				power-amplifier-output = "rfo-hp";      /* in zephyr\boards\st\nucleo_wl55jc\nucleo_wl55jc.dts:202 */
				rfo-lp-max-power = < 0xf >;             /* in zephyr\boards\st\nucleo_wl55jc\nucleo_wl55jc.dts:203 */
				rfo-hp-max-power = < 0x16 >;            /* in zephyr\boards\st\nucleo_wl55jc\nucleo_wl55jc.dts:204 */
			};
		};

		/* node '/soc/adc@40012400' defined in zephyr\dts\arm\st\wl\stm32wl.dtsi:356 */
		adc1: adc@40012400 {
			compatible = "st,stm32-adc";                              /* in zephyr\dts\arm\st\wl\stm32wl.dtsi:357 */
			reg = < 0x40012400 0x400 >;                               /* in zephyr\dts\arm\st\wl\stm32wl.dtsi:358 */
			clocks = < &rcc 0x60 0x200 >;                             /* in zephyr\dts\arm\st\wl\stm32wl.dtsi:359 */
			clock-names = "adcx";                                     /* in zephyr\dts\arm\st\wl\stm32wl.dtsi:360 */
			interrupts = < 0x12 0x0 >;                                /* in zephyr\dts\arm\st\wl\stm32wl.dtsi:361 */
			#io-channel-cells = < 0x1 >;                              /* in zephyr\dts\arm\st\wl\stm32wl.dtsi:362 */
			resolutions = < 0x60630c 0x51630c 0x42630c 0x33630c >;    /* in zephyr\dts\arm\st\wl\stm32wl.dtsi:363 */
			sampling-times = < 0x2 0x4 0x8 0xd 0x14 0x28 0x50 0xa1 >; /* in zephyr\dts\arm\st\wl\stm32wl.dtsi:367 */
			num-sampling-time-common-channels = < 0x2 >;              /* in zephyr\dts\arm\st\wl\stm32wl.dtsi:368 */
			st,adc-sequencer = "fixed";                               /* in zephyr\dts\arm\st\wl\stm32wl.dtsi:369 */
			st,adc-oversampler = "minimal";                           /* in zephyr\dts\arm\st\wl\stm32wl.dtsi:370 */
			st,adc-internal-regulator = "startup-sw-delay";           /* in zephyr\dts\arm\st\wl\stm32wl.dtsi:371 */
			st,adc-clock-source = "SYNC";                             /* in zephyr\boards\st\nucleo_wl55jc\nucleo_wl55jc.dts:166 */
			st,adc-prescaler = < 0x4 >;                               /* in zephyr\boards\st\nucleo_wl55jc\nucleo_wl55jc.dts:167 */
			status = "okay";                                          /* in ..\Downloads\blink_basic\build\zephyr\boards\nucleo_wl55jc.overlay:43 */
			pinctrl-0 = < &adc1_in0_pa0 &adc1_in1_pa1 >;              /* in ..\Downloads\blink_basic\build\zephyr\boards\nucleo_wl55jc.overlay:44 */
			pinctrl-names = "default";                                /* in ..\Downloads\blink_basic\build\zephyr\boards\nucleo_wl55jc.overlay:45 */
			#address-cells = < 0x1 >;                                 /* in ..\Downloads\blink_basic\build\zephyr\boards\nucleo_wl55jc.overlay:46 */
			#size-cells = < 0x0 >;                                    /* in ..\Downloads\blink_basic\build\zephyr\boards\nucleo_wl55jc.overlay:47 */
			phandle = < 0x1b >;                                       /* in zephyr\dts\arm\st\wl\stm32wl.dtsi:559 */

			/* node '/soc/adc@40012400/channel@0' defined in ..\Downloads\blink_basic\build\zephyr\boards\nucleo_wl55jc.overlay:49 */
			channel@0 {
				reg = < 0x0 >;                         /* in ..\Downloads\blink_basic\build\zephyr\boards\nucleo_wl55jc.overlay:50 */
				zephyr,gain = "ADC_GAIN_1";            /* in ..\Downloads\blink_basic\build\zephyr\boards\nucleo_wl55jc.overlay:51 */
				zephyr,reference = "ADC_REF_INTERNAL"; /* in ..\Downloads\blink_basic\build\zephyr\boards\nucleo_wl55jc.overlay:52 */
				zephyr,acquisition-time = < 0x0 >;     /* in ..\Downloads\blink_basic\build\zephyr\boards\nucleo_wl55jc.overlay:53 */
				zephyr,resolution = < 0xc >;           /* in ..\Downloads\blink_basic\build\zephyr\boards\nucleo_wl55jc.overlay:54 */
			};

			/* node '/soc/adc@40012400/channel@1' defined in ..\Downloads\blink_basic\build\zephyr\boards\nucleo_wl55jc.overlay:57 */
			channel@1 {
				reg = < 0x1 >;                         /* in ..\Downloads\blink_basic\build\zephyr\boards\nucleo_wl55jc.overlay:58 */
				zephyr,gain = "ADC_GAIN_1";            /* in ..\Downloads\blink_basic\build\zephyr\boards\nucleo_wl55jc.overlay:59 */
				zephyr,reference = "ADC_REF_INTERNAL"; /* in ..\Downloads\blink_basic\build\zephyr\boards\nucleo_wl55jc.overlay:60 */
				zephyr,acquisition-time = < 0x0 >;     /* in ..\Downloads\blink_basic\build\zephyr\boards\nucleo_wl55jc.overlay:61 */
				zephyr,resolution = < 0xc >;           /* in ..\Downloads\blink_basic\build\zephyr\boards\nucleo_wl55jc.overlay:62 */
			};
		};

		/* node '/soc/dac@40007400' defined in zephyr\dts\arm\st\wl\stm32wl.dtsi:375 */
		dac1: dac@40007400 {
			compatible = "st,stm32-dac";       /* in zephyr\dts\arm\st\wl\stm32wl.dtsi:376 */
			reg = < 0x40007400 0x400 >;        /* in zephyr\dts\arm\st\wl\stm32wl.dtsi:377 */
			clocks = < &rcc 0x58 0x20000000 >; /* in zephyr\dts\arm\st\wl\stm32wl.dtsi:378 */
			#io-channel-cells = < 0x1 >;       /* in zephyr\dts\arm\st\wl\stm32wl.dtsi:380 */
			pinctrl-0 = < &dac_out1_pa10 >;    /* in zephyr\boards\st\nucleo_wl55jc\nucleo_wl55jc.dts:147 */
			pinctrl-names = "default";         /* in zephyr\boards\st\nucleo_wl55jc\nucleo_wl55jc.dts:148 */
			status = "okay";                   /* in zephyr\boards\st\nucleo_wl55jc\nucleo_wl55jc.dts:149 */
		};

		/* node '/soc/timers@40012c00' defined in zephyr\dts\arm\st\wl\stm32wl.dtsi:383 */
		timers1: timers@40012c00 {
			compatible = "st,stm32-timers"; /* in zephyr\dts\arm\st\wl\stm32wl.dtsi:384 */
			reg = < 0x40012c00 0x400 >;     /* in zephyr\dts\arm\st\wl\stm32wl.dtsi:385 */
			clocks = < &rcc 0x60 0x800 >,
			         < &rcc 0x8 0xff >;     /* in zephyr\dts\arm\st\wl\stm32wl.dtsi:386 */
			resets = < &rctl 0x80b >;       /* in zephyr\dts\arm\st\wl\stm32wl.dtsi:388 */
			interrupts = < 0x17 0x0 >,
			             < 0x18 0x0 >,
			             < 0x19 0x0 >,
			             < 0x1a 0x0 >;      /* in zephyr\dts\arm\st\wl\stm32wl.dtsi:389 */
			interrupt-names = "brk",
			                  "up",
			                  "trgcom",
			                  "cc";         /* in zephyr\dts\arm\st\wl\stm32wl.dtsi:390 */
			st,prescaler = < 0x0 >;         /* in zephyr\dts\arm\st\wl\stm32wl.dtsi:391 */
			status = "disabled";            /* in zephyr\dts\arm\st\wl\stm32wl.dtsi:392 */

			/* node '/soc/timers@40012c00/pwm' defined in zephyr\dts\arm\st\wl\stm32wl.dtsi:394 */
			pwm {
				compatible = "st,stm32-pwm"; /* in zephyr\dts\arm\st\wl\stm32wl.dtsi:395 */
				status = "disabled";         /* in zephyr\dts\arm\st\wl\stm32wl.dtsi:396 */
				#pwm-cells = < 0x3 >;        /* in zephyr\dts\arm\st\wl\stm32wl.dtsi:397 */
			};
		};

		/* node '/soc/timers@40000000' defined in zephyr\dts\arm\st\wl\stm32wl.dtsi:401 */
		timers2: timers@40000000 {
			compatible = "st,stm32-timers"; /* in zephyr\dts\arm\st\wl\stm32wl.dtsi:402 */
			reg = < 0x40000000 0x400 >;     /* in zephyr\dts\arm\st\wl\stm32wl.dtsi:403 */
			clocks = < &rcc 0x58 0x1 >,
			         < &rcc 0x7 0xff >;     /* in zephyr\dts\arm\st\wl\stm32wl.dtsi:404 */
			resets = < &rctl 0x700 >;       /* in zephyr\dts\arm\st\wl\stm32wl.dtsi:406 */
			interrupts = < 0x1b 0x0 >;      /* in zephyr\dts\arm\st\wl\stm32wl.dtsi:407 */
			interrupt-names = "global";     /* in zephyr\dts\arm\st\wl\stm32wl.dtsi:408 */
			st,prescaler = < 0x0 >;         /* in zephyr\dts\arm\st\wl\stm32wl.dtsi:409 */
			status = "okay";                /* in zephyr\boards\st\nucleo_wl55jc\nucleo_wl55jc.dts:153 */

			/* node '/soc/timers@40000000/pwm' defined in zephyr\dts\arm\st\wl\stm32wl.dtsi:412 */
			pwm2: pwm {
				compatible = "st,stm32-pwm";    /* in zephyr\dts\arm\st\wl\stm32wl.dtsi:413 */
				#pwm-cells = < 0x3 >;           /* in zephyr\dts\arm\st\wl\stm32wl.dtsi:415 */
				status = "okay";                /* in zephyr\boards\st\nucleo_wl55jc\nucleo_wl55jc.dts:157 */
				pinctrl-0 = < &tim2_ch4_pb11 >; /* in zephyr\boards\st\nucleo_wl55jc\nucleo_wl55jc.dts:158 */
				pinctrl-names = "default";      /* in zephyr\boards\st\nucleo_wl55jc\nucleo_wl55jc.dts:159 */
			};

			/* node '/soc/timers@40000000/counter' defined in zephyr\dts\arm\st\wl\stm32wl.dtsi:418 */
			counter {
				compatible = "st,stm32-counter"; /* in zephyr\dts\arm\st\wl\stm32wl.dtsi:419 */
				status = "disabled";             /* in zephyr\dts\arm\st\wl\stm32wl.dtsi:420 */
			};
		};

		/* node '/soc/timers@40014400' defined in zephyr\dts\arm\st\wl\stm32wl.dtsi:424 */
		timers16: timers@40014400 {
			compatible = "st,stm32-timers"; /* in zephyr\dts\arm\st\wl\stm32wl.dtsi:425 */
			reg = < 0x40014400 0x400 >;     /* in zephyr\dts\arm\st\wl\stm32wl.dtsi:426 */
			clocks = < &rcc 0x60 0x20000 >,
			         < &rcc 0x8 0xff >;     /* in zephyr\dts\arm\st\wl\stm32wl.dtsi:427 */
			resets = < &rctl 0x811 >;       /* in zephyr\dts\arm\st\wl\stm32wl.dtsi:429 */
			interrupts = < 0x1c 0x0 >;      /* in zephyr\dts\arm\st\wl\stm32wl.dtsi:430 */
			interrupt-names = "global";     /* in zephyr\dts\arm\st\wl\stm32wl.dtsi:431 */
			st,prescaler = < 0x0 >;         /* in zephyr\dts\arm\st\wl\stm32wl.dtsi:432 */
			status = "disabled";            /* in zephyr\dts\arm\st\wl\stm32wl.dtsi:433 */

			/* node '/soc/timers@40014400/pwm' defined in zephyr\dts\arm\st\wl\stm32wl.dtsi:435 */
			pwm {
				compatible = "st,stm32-pwm"; /* in zephyr\dts\arm\st\wl\stm32wl.dtsi:436 */
				status = "disabled";         /* in zephyr\dts\arm\st\wl\stm32wl.dtsi:437 */
				#pwm-cells = < 0x3 >;        /* in zephyr\dts\arm\st\wl\stm32wl.dtsi:438 */
			};

			/* node '/soc/timers@40014400/counter' defined in zephyr\dts\arm\st\wl\stm32wl.dtsi:441 */
			counter {
				compatible = "st,stm32-counter"; /* in zephyr\dts\arm\st\wl\stm32wl.dtsi:442 */
				status = "disabled";             /* in zephyr\dts\arm\st\wl\stm32wl.dtsi:443 */
			};
		};

		/* node '/soc/timers@40014800' defined in zephyr\dts\arm\st\wl\stm32wl.dtsi:447 */
		timers17: timers@40014800 {
			compatible = "st,stm32-timers"; /* in zephyr\dts\arm\st\wl\stm32wl.dtsi:448 */
			reg = < 0x40014800 0x400 >;     /* in zephyr\dts\arm\st\wl\stm32wl.dtsi:449 */
			clocks = < &rcc 0x60 0x40000 >,
			         < &rcc 0x8 0xff >;     /* in zephyr\dts\arm\st\wl\stm32wl.dtsi:450 */
			resets = < &rctl 0x812 >;       /* in zephyr\dts\arm\st\wl\stm32wl.dtsi:452 */
			interrupts = < 0x1d 0x0 >;      /* in zephyr\dts\arm\st\wl\stm32wl.dtsi:453 */
			interrupt-names = "global";     /* in zephyr\dts\arm\st\wl\stm32wl.dtsi:454 */
			st,prescaler = < 0x0 >;         /* in zephyr\dts\arm\st\wl\stm32wl.dtsi:455 */
			status = "disabled";            /* in zephyr\dts\arm\st\wl\stm32wl.dtsi:456 */

			/* node '/soc/timers@40014800/pwm' defined in zephyr\dts\arm\st\wl\stm32wl.dtsi:458 */
			pwm {
				compatible = "st,stm32-pwm"; /* in zephyr\dts\arm\st\wl\stm32wl.dtsi:459 */
				status = "disabled";         /* in zephyr\dts\arm\st\wl\stm32wl.dtsi:460 */
				#pwm-cells = < 0x3 >;        /* in zephyr\dts\arm\st\wl\stm32wl.dtsi:461 */
			};

			/* node '/soc/timers@40014800/counter' defined in zephyr\dts\arm\st\wl\stm32wl.dtsi:464 */
			counter {
				compatible = "st,stm32-counter"; /* in zephyr\dts\arm\st\wl\stm32wl.dtsi:465 */
				status = "disabled";             /* in zephyr\dts\arm\st\wl\stm32wl.dtsi:466 */
			};
		};

		/* node '/soc/aes@58001800' defined in zephyr\dts\arm\st\wl\stm32wl.dtsi:470 */
		aes: aes@58001800 {
			compatible = "st,stm32-aes";    /* in zephyr\dts\arm\st\wl\stm32wl.dtsi:471 */
			reg = < 0x58001800 0x400 >;     /* in zephyr\dts\arm\st\wl\stm32wl.dtsi:472 */
			clocks = < &rcc 0x50 0x20000 >; /* in zephyr\dts\arm\st\wl\stm32wl.dtsi:473 */
			resets = < &rctl 0x610 >;       /* in zephyr\dts\arm\st\wl\stm32wl.dtsi:474 */
			interrupts = < 0x33 0x0 >;      /* in zephyr\dts\arm\st\wl\stm32wl.dtsi:475 */
			status = "okay";                /* in zephyr\boards\st\nucleo_wl55jc\nucleo_wl55jc.dts:176 */
		};

		/* node '/soc/rng@58001000' defined in zephyr\dts\arm\st\wl\stm32wl.dtsi:479 */
		rng: rng@58001000 {
			compatible = "st,stm32-rng";        /* in zephyr\dts\arm\st\wl\stm32wl.dtsi:480 */
			reg = < 0x58001000 0x400 >;         /* in zephyr\dts\arm\st\wl\stm32wl.dtsi:481 */
			interrupts = < 0x34 0x0 >;          /* in zephyr\dts\arm\st\wl\stm32wl.dtsi:482 */
			clocks = < &rcc 0x50 0x40000 >;     /* in zephyr\dts\arm\st\wl\stm32wl.dtsi:483 */
			health-test-magic = < 0x17590abc >; /* in zephyr\dts\arm\st\wl\stm32wl.dtsi:484 */
			health-test-config = < 0xaa74 >;    /* in zephyr\dts\arm\st\wl\stm32wl.dtsi:485 */
			status = "okay";                    /* in zephyr\boards\st\nucleo_wl55jc\nucleo_wl55jc.dts:180 */
		};

		/* node '/soc/dma@40020000' defined in zephyr\dts\arm\st\wl\stm32wl.dtsi:489 */
		dma1: dma@40020000 {
			compatible = "st,stm32-dma-v2";                                             /* in zephyr\dts\arm\st\wl\stm32wl.dtsi:490 */
			#dma-cells = < 0x3 >;                                                       /* in zephyr\dts\arm\st\wl\stm32wl.dtsi:491 */
			reg = < 0x40020000 0x400 >;                                                 /* in zephyr\dts\arm\st\wl\stm32wl.dtsi:492 */
			interrupts = < 0xb 0x0 0xc 0x0 0xd 0x0 0xe 0x0 0xf 0x0 0x10 0x0 0x11 0x0 >; /* in zephyr\dts\arm\st\wl\stm32wl.dtsi:493 */
			clocks = < &rcc 0x48 0x1 >;                                                 /* in zephyr\dts\arm\st\wl\stm32wl.dtsi:494 */
			dma-requests = < 0x7 >;                                                     /* in zephyr\dts\arm\st\wl\stm32wl.dtsi:495 */
			dma-offset = < 0x0 >;                                                       /* in zephyr\dts\arm\st\wl\stm32wl.dtsi:496 */
			status = "disabled";                                                        /* in zephyr\dts\arm\st\wl\stm32wl.dtsi:497 */
		};

		/* node '/soc/dma@40020400' defined in zephyr\dts\arm\st\wl\stm32wl.dtsi:500 */
		dma2: dma@40020400 {
			compatible = "st,stm32-dma-v2";                                                  /* in zephyr\dts\arm\st\wl\stm32wl.dtsi:501 */
			#dma-cells = < 0x3 >;                                                            /* in zephyr\dts\arm\st\wl\stm32wl.dtsi:502 */
			reg = < 0x40020400 0x400 >;                                                      /* in zephyr\dts\arm\st\wl\stm32wl.dtsi:503 */
			interrupts = < 0x36 0x0 0x37 0x0 0x38 0x0 0x39 0x0 0x3a 0x0 0x3b 0x0 0x3c 0x0 >; /* in zephyr\dts\arm\st\wl\stm32wl.dtsi:504 */
			clocks = < &rcc 0x48 0x2 >;                                                      /* in zephyr\dts\arm\st\wl\stm32wl.dtsi:505 */
			dma-requests = < 0x7 >;                                                          /* in zephyr\dts\arm\st\wl\stm32wl.dtsi:506 */
			dma-offset = < 0x7 >;                                                            /* in zephyr\dts\arm\st\wl\stm32wl.dtsi:507 */
			status = "disabled";                                                             /* in zephyr\dts\arm\st\wl\stm32wl.dtsi:508 */
		};

		/* node '/soc/dmamux@40020800' defined in zephyr\dts\arm\st\wl\stm32wl.dtsi:511 */
		dmamux1: dmamux@40020800 {
			compatible = "st,stm32-dmamux"; /* in zephyr\dts\arm\st\wl\stm32wl.dtsi:512 */
			#dma-cells = < 0x3 >;           /* in zephyr\dts\arm\st\wl\stm32wl.dtsi:513 */
			reg = < 0x40020800 0x400 >;     /* in zephyr\dts\arm\st\wl\stm32wl.dtsi:514 */
			interrupts = < 0x3d 0x0 >;      /* in zephyr\dts\arm\st\wl\stm32wl.dtsi:515 */
			clocks = < &rcc 0x48 0x4 >;     /* in zephyr\dts\arm\st\wl\stm32wl.dtsi:516 */
			dma-channels = < 0xe >;         /* in zephyr\dts\arm\st\wl\stm32wl.dtsi:517 */
			dma-generators = < 0x4 >;       /* in zephyr\dts\arm\st\wl\stm32wl.dtsi:518 */
			dma-requests = < 0x26 >;        /* in zephyr\dts\arm\st\wl\stm32wl.dtsi:519 */
			status = "disabled";            /* in zephyr\dts\arm\st\wl\stm32wl.dtsi:520 */
		};

		/* node '/soc/power@58000400' defined in zephyr\dts\arm\st\wl\stm32wl.dtsi:523 */
		pwr: power@58000400 {
			compatible = "st,stm32-pwr"; /* in zephyr\dts\arm\st\wl\stm32wl.dtsi:524 */
			reg = < 0x58000400 0x400 >;  /* in zephyr\dts\arm\st\wl\stm32wl.dtsi:525 */
			status = "disabled";         /* in zephyr\dts\arm\st\wl\stm32wl.dtsi:526 */
			wkup-pins-nb = < 0x3 >;      /* in zephyr\dts\arm\st\wl\stm32wl.dtsi:528 */
			wkup-pins-pol;               /* in zephyr\dts\arm\st\wl\stm32wl.dtsi:529 */
			wkup-pins-pupd;              /* in zephyr\dts\arm\st\wl\stm32wl.dtsi:530 */
			#address-cells = < 0x1 >;    /* in zephyr\dts\arm\st\wl\stm32wl.dtsi:532 */
			#size-cells = < 0x0 >;       /* in zephyr\dts\arm\st\wl\stm32wl.dtsi:533 */

			/* node '/soc/power@58000400/wkup-pin@1' defined in zephyr\dts\arm\st\wl\stm32wl.dtsi:535 */
			wkup-pin@1 {
				reg = < 0x1 >;                   /* in zephyr\dts\arm\st\wl\stm32wl.dtsi:536 */
				wkup-gpios = < &gpioa 0x0 0x1 >; /* in zephyr\dts\arm\st\wl\stm32wl.dtsi:537 */
			};

			/* node '/soc/power@58000400/wkup-pin@2' defined in zephyr\dts\arm\st\wl\stm32wl.dtsi:540 */
			wkup-pin@2 {
				reg = < 0x2 >;                   /* in zephyr\dts\arm\st\wl\stm32wl.dtsi:541 */
				wkup-gpios = < &gpioc 0xd 0x1 >; /* in zephyr\dts\arm\st\wl\stm32wl.dtsi:542 */
			};

			/* node '/soc/power@58000400/wkup-pin@3' defined in zephyr\dts\arm\st\wl\stm32wl.dtsi:545 */
			wkup-pin@3 {
				reg = < 0x3 >;                   /* in zephyr\dts\arm\st\wl\stm32wl.dtsi:546 */
				wkup-gpios = < &gpiob 0x3 0x1 >; /* in zephyr\dts\arm\st\wl\stm32wl.dtsi:547 */
			};
		};
	};

	/* node '/cpus' defined in zephyr\dts\arm\st\wl\stm32wl.dtsi:28 */
	cpus {
		#address-cells = < 0x1 >; /* in zephyr\dts\arm\st\wl\stm32wl.dtsi:29 */
		#size-cells = < 0x0 >;    /* in zephyr\dts\arm\st\wl\stm32wl.dtsi:30 */

		/* node '/cpus/cpu@0' defined in zephyr\dts\arm\st\wl\stm32wl.dtsi:32 */
		cpu0: cpu@0 {
			device_type = "cpu";                         /* in zephyr\dts\arm\st\wl\stm32wl.dtsi:33 */
			compatible = "arm,cortex-m4";                /* in zephyr\dts\arm\st\wl\stm32wl.dtsi:34 */
			reg = < 0x0 >;                               /* in zephyr\dts\arm\st\wl\stm32wl.dtsi:35 */
			cpu-power-states = < &stop0 &stop1 &stop2 >; /* in zephyr\dts\arm\st\wl\stm32wl.dtsi:36 */
		};

		/* node '/cpus/power-states' defined in zephyr\dts\arm\st\wl\stm32wl.dtsi:39 */
		power-states {

			/* node '/cpus/power-states/state0' defined in zephyr\dts\arm\st\wl\stm32wl.dtsi:40 */
			stop0: state0 {
				compatible = "zephyr,power-state";    /* in zephyr\dts\arm\st\wl\stm32wl.dtsi:41 */
				power-state-name = "suspend-to-idle"; /* in zephyr\dts\arm\st\wl\stm32wl.dtsi:42 */
				substate-id = < 0x1 >;                /* in zephyr\dts\arm\st\wl\stm32wl.dtsi:43 */
				min-residency-us = < 0x64 >;          /* in zephyr\dts\arm\st\wl\stm32wl.dtsi:44 */
				phandle = < 0x17 >;                   /* in zephyr\dts\arm\st\wl\stm32wl.dtsi:36 */
			};

			/* node '/cpus/power-states/state1' defined in zephyr\dts\arm\st\wl\stm32wl.dtsi:47 */
			stop1: state1 {
				compatible = "zephyr,power-state";    /* in zephyr\dts\arm\st\wl\stm32wl.dtsi:48 */
				power-state-name = "suspend-to-idle"; /* in zephyr\dts\arm\st\wl\stm32wl.dtsi:49 */
				substate-id = < 0x2 >;                /* in zephyr\dts\arm\st\wl\stm32wl.dtsi:50 */
				min-residency-us = < 0x1f4 >;         /* in zephyr\dts\arm\st\wl\stm32wl.dtsi:51 */
				phandle = < 0x18 >;                   /* in zephyr\dts\arm\st\wl\stm32wl.dtsi:36 */
			};

			/* node '/cpus/power-states/state2' defined in zephyr\dts\arm\st\wl\stm32wl.dtsi:54 */
			stop2: state2 {
				compatible = "zephyr,power-state";    /* in zephyr\dts\arm\st\wl\stm32wl.dtsi:55 */
				power-state-name = "suspend-to-idle"; /* in zephyr\dts\arm\st\wl\stm32wl.dtsi:56 */
				substate-id = < 0x3 >;                /* in zephyr\dts\arm\st\wl\stm32wl.dtsi:57 */
				min-residency-us = < 0x384 >;         /* in zephyr\dts\arm\st\wl\stm32wl.dtsi:58 */
				phandle = < 0x19 >;                   /* in zephyr\dts\arm\st\wl\stm32wl.dtsi:36 */
			};
		};
	};

	/* node '/memory@20000000' defined in zephyr\dts\arm\st\wl\stm32wl.dtsi:63 */
	sram0: memory@20000000 {
		compatible = "zephyr,memory-region",
		             "mmio-sram";            /* in zephyr\dts\arm\st\wl\stm32wl.dtsi:64 */
		zephyr,memory-region = "SRAM0";      /* in zephyr\dts\arm\st\wl\stm32wl.dtsi:65 */
		reg = < 0x20000000 0x10000 >;        /* in zephyr\dts\arm\st\wl\stm32wl55Xc.dtsi:10 */
	};

	/* node '/clocks' defined in zephyr\dts\arm\st\wl\stm32wl.dtsi:68 */
	clocks {

		/* node '/clocks/clk-hse' defined in zephyr\dts\arm\st\wl\stm32wl.dtsi:69 */
		clk_hse: clk-hse {
			#clock-cells = < 0x0 >;              /* in zephyr\dts\arm\st\wl\stm32wl.dtsi:70 */
			compatible = "st,stm32wl-hse-clock"; /* in zephyr\dts\arm\st\wl\stm32wl.dtsi:71 */
			clock-frequency = < 0x1e84800 >;     /* in zephyr\dts\arm\st\wl\stm32wl.dtsi:73 */
			status = "disabled";                 /* in zephyr\dts\arm\st\wl\stm32wl.dtsi:74 */
		};

		/* node '/clocks/clk-hsi' defined in zephyr\dts\arm\st\wl\stm32wl.dtsi:77 */
		clk_hsi: clk-hsi {
			#clock-cells = < 0x0 >;         /* in zephyr\dts\arm\st\wl\stm32wl.dtsi:78 */
			compatible = "fixed-clock";     /* in zephyr\dts\arm\st\wl\stm32wl.dtsi:79 */
			clock-frequency = < 0xf42400 >; /* in zephyr\dts\arm\st\wl\stm32wl.dtsi:80 */
			status = "okay";                /* in zephyr\boards\st\nucleo_wl55jc\nucleo_wl55jc.dts:99 */
			phandle = < 0x1a >;             /* in zephyr\boards\st\nucleo_wl55jc\nucleo_wl55jc.dts:111 */
		};

		/* node '/clocks/clk-msi' defined in zephyr\dts\arm\st\wl\stm32wl.dtsi:84 */
		clk_msi: clk-msi {
			#clock-cells = < 0x0 >;            /* in zephyr\dts\arm\st\wl\stm32wl.dtsi:85 */
			compatible = "st,stm32-msi-clock"; /* in zephyr\dts\arm\st\wl\stm32wl.dtsi:86 */
			msi-range = < 0x6 >;               /* in zephyr\dts\arm\st\wl\stm32wl.dtsi:87 */
			status = "disabled";               /* in zephyr\dts\arm\st\wl\stm32wl.dtsi:88 */
		};

		/* node '/clocks/clk-lse' defined in zephyr\dts\arm\st\wl\stm32wl.dtsi:91 */
		clk_lse: clk-lse {
			#clock-cells = < 0x0 >;            /* in zephyr\dts\arm\st\wl\stm32wl.dtsi:92 */
			compatible = "st,stm32-lse-clock"; /* in zephyr\dts\arm\st\wl\stm32wl.dtsi:93 */
			clock-frequency = < 0x8000 >;      /* in zephyr\dts\arm\st\wl\stm32wl.dtsi:94 */
			driving-capability = < 0x0 >;      /* in zephyr\dts\arm\st\wl\stm32wl.dtsi:95 */
			status = "okay";                   /* in zephyr\boards\st\nucleo_wl55jc\nucleo_wl55jc.dts:103 */
		};

		/* node '/clocks/clk-lsi' defined in zephyr\dts\arm\st\wl\stm32wl.dtsi:99 */
		clk_lsi: clk-lsi {
			#clock-cells = < 0x0 >;       /* in zephyr\dts\arm\st\wl\stm32wl.dtsi:100 */
			compatible = "fixed-clock";   /* in zephyr\dts\arm\st\wl\stm32wl.dtsi:101 */
			clock-frequency = < 0x7d00 >; /* in zephyr\dts\arm\st\wl\stm32wl.dtsi:102 */
			status = "okay";              /* in zephyr\boards\st\nucleo_wl55jc\nucleo_wl55jc.dts:88 */
		};

		/* node '/clocks/pll' defined in zephyr\dts\arm\st\wl\stm32wl.dtsi:106 */
		pll: pll {
			#clock-cells = < 0x0 >;              /* in zephyr\dts\arm\st\wl\stm32wl.dtsi:107 */
			compatible = "st,stm32wb-pll-clock"; /* in zephyr\dts\arm\st\wl\stm32wl.dtsi:108 */
			div-m = < 0x1 >;                     /* in zephyr\boards\st\nucleo_wl55jc\nucleo_wl55jc.dts:107 */
			mul-n = < 0x6 >;                     /* in zephyr\boards\st\nucleo_wl55jc\nucleo_wl55jc.dts:108 */
			div-r = < 0x2 >;                     /* in zephyr\boards\st\nucleo_wl55jc\nucleo_wl55jc.dts:109 */
			div-q = < 0x2 >;                     /* in zephyr\boards\st\nucleo_wl55jc\nucleo_wl55jc.dts:110 */
			clocks = < &clk_hsi >;               /* in zephyr\boards\st\nucleo_wl55jc\nucleo_wl55jc.dts:111 */
			status = "okay";                     /* in zephyr\boards\st\nucleo_wl55jc\nucleo_wl55jc.dts:112 */
			phandle = < 0x2 >;                   /* in zephyr\boards\st\nucleo_wl55jc\nucleo_wl55jc.dts:116 */
		};
	};

	/* node '/mcos' defined in zephyr\dts\arm\st\wl\stm32wl.dtsi:113 */
	mcos {

		/* node '/mcos/mco1' defined in zephyr\dts\arm\st\wl\stm32wl.dtsi:114 */
		mco1: mco1 {
			compatible = "st,stm32-clock-mco"; /* in zephyr\dts\arm\st\wl\stm32wl.dtsi:115 */
			status = "disabled";               /* in zephyr\dts\arm\st\wl\stm32wl.dtsi:116 */
		};
	};

	/* node '/dietemp' defined in zephyr\dts\arm\st\wl\stm32wl.dtsi:552 */
	die_temp: dietemp {
		compatible = "st,stm32-temp-cal"; /* in zephyr\dts\arm\st\wl\stm32wl.dtsi:553 */
		ts-cal1-addr = < 0x1fff75a8 >;    /* in zephyr\dts\arm\st\wl\stm32wl.dtsi:554 */
		ts-cal2-addr = < 0x1fff75c8 >;    /* in zephyr\dts\arm\st\wl\stm32wl.dtsi:555 */
		ts-cal1-temp = < 0x1e >;          /* in zephyr\dts\arm\st\wl\stm32wl.dtsi:556 */
		ts-cal2-temp = < 0x82 >;          /* in zephyr\dts\arm\st\wl\stm32wl.dtsi:557 */
		ts-cal-vrefanalog = < 0xce4 >;    /* in zephyr\dts\arm\st\wl\stm32wl.dtsi:558 */
		io-channels = < &adc1 0xc >;      /* in zephyr\dts\arm\st\wl\stm32wl.dtsi:559 */
		status = "okay";                  /* in zephyr\boards\st\nucleo_wl55jc\nucleo_wl55jc.dts:172 */
	};

	/* node '/vref' defined in zephyr\dts\arm\st\wl\stm32wl.dtsi:563 */
	vref: vref {
		compatible = "st,stm32-vref";      /* in zephyr\dts\arm\st\wl\stm32wl.dtsi:564 */
		vrefint-cal-addr = < 0x1fff75aa >; /* in zephyr\dts\arm\st\wl\stm32wl.dtsi:565 */
		vrefint-cal-mv = < 0xce4 >;        /* in zephyr\dts\arm\st\wl\stm32wl.dtsi:566 */
		io-channels = < &adc1 0xd >;       /* in zephyr\dts\arm\st\wl\stm32wl.dtsi:567 */
		status = "okay";                   /* in zephyr\boards\st\nucleo_wl55jc\nucleo_wl55jc.dts:252 */
	};

	/* node '/vbat' defined in zephyr\dts\arm\st\wl\stm32wl.dtsi:571 */
	vbat: vbat {
		compatible = "st,stm32-vbat"; /* in zephyr\dts\arm\st\wl\stm32wl.dtsi:572 */
		ratio = < 0x3 >;              /* in zephyr\dts\arm\st\wl\stm32wl.dtsi:573 */
		io-channels = < &adc1 0xe >;  /* in zephyr\dts\arm\st\wl\stm32wl.dtsi:574 */
		status = "okay";              /* in zephyr\boards\st\nucleo_wl55jc\nucleo_wl55jc.dts:256 */
	};

	/* node '/smbus1' defined in zephyr\dts\arm\st\wl\stm32wl.dtsi:578 */
	smbus1: smbus1 {
		compatible = "st,stm32-smbus"; /* in zephyr\dts\arm\st\wl\stm32wl.dtsi:579 */
		#address-cells = < 0x1 >;      /* in zephyr\dts\arm\st\wl\stm32wl.dtsi:580 */
		#size-cells = < 0x0 >;         /* in zephyr\dts\arm\st\wl\stm32wl.dtsi:581 */
		i2c = < &i2c1 >;               /* in zephyr\dts\arm\st\wl\stm32wl.dtsi:582 */
		status = "disabled";           /* in zephyr\dts\arm\st\wl\stm32wl.dtsi:583 */
	};

	/* node '/smbus2' defined in zephyr\dts\arm\st\wl\stm32wl.dtsi:586 */
	smbus2: smbus2 {
		compatible = "st,stm32-smbus"; /* in zephyr\dts\arm\st\wl\stm32wl.dtsi:587 */
		#address-cells = < 0x1 >;      /* in zephyr\dts\arm\st\wl\stm32wl.dtsi:588 */
		#size-cells = < 0x0 >;         /* in zephyr\dts\arm\st\wl\stm32wl.dtsi:589 */
		i2c = < &i2c2 >;               /* in zephyr\dts\arm\st\wl\stm32wl.dtsi:590 */
		status = "disabled";           /* in zephyr\dts\arm\st\wl\stm32wl.dtsi:591 */
	};

	/* node '/smbus3' defined in zephyr\dts\arm\st\wl\stm32wl.dtsi:594 */
	smbus3: smbus3 {
		compatible = "st,stm32-smbus"; /* in zephyr\dts\arm\st\wl\stm32wl.dtsi:595 */
		#address-cells = < 0x1 >;      /* in zephyr\dts\arm\st\wl\stm32wl.dtsi:596 */
		#size-cells = < 0x0 >;         /* in zephyr\dts\arm\st\wl\stm32wl.dtsi:597 */
		i2c = < &i2c3 >;               /* in zephyr\dts\arm\st\wl\stm32wl.dtsi:598 */
		status = "disabled";           /* in zephyr\dts\arm\st\wl\stm32wl.dtsi:599 */
	};

	/* node '/connector' defined in zephyr\boards\st\nucleo_wl55jc\arduino_r3_connector.dtsi:10 */
	arduino_header: connector {
		compatible = "arduino-header-r3";          /* in zephyr\boards\st\nucleo_wl55jc\arduino_r3_connector.dtsi:11 */
		#gpio-cells = < 0x2 >;                     /* in zephyr\boards\st\nucleo_wl55jc\arduino_r3_connector.dtsi:12 */
		gpio-map-mask = < 0xffffffff 0xffffffc0 >; /* in zephyr\boards\st\nucleo_wl55jc\arduino_r3_connector.dtsi:13 */
		gpio-map-pass-thru = < 0x0 0x3f >;         /* in zephyr\boards\st\nucleo_wl55jc\arduino_r3_connector.dtsi:14 */
		gpio-map = < 0x0 0x0 &gpiob 0x1 0x0 >,
		           < 0x1 0x0 &gpiob 0x2 0x0 >,
		           < 0x2 0x0 &gpioa 0xa 0x0 >,
		           < 0x3 0x0 &gpiob 0x4 0x0 >,
		           < 0x4 0x0 &gpiob 0xe 0x0 >,
		           < 0x5 0x0 &gpiob 0xd 0x0 >,
		           < 0x6 0x0 &gpiob 0x7 0x0 >,
		           < 0x7 0x0 &gpiob 0x6 0x0 >,
		           < 0x8 0x0 &gpiob 0xc 0x0 >,
		           < 0x9 0x0 &gpiob 0x3 0x0 >,
		           < 0xa 0x0 &gpiob 0x5 0x0 >,
		           < 0xb 0x0 &gpiob 0x8 0x0 >,
		           < 0xc 0x0 &gpiob 0xa 0x0 >,
		           < 0xd 0x0 &gpioc 0x1 0x0 >,
		           < 0xe 0x0 &gpioc 0x2 0x0 >,
		           < 0xf 0x0 &gpioa 0x9 0x0 >,
		           < 0x10 0x0 &gpioa 0x4 0x0 >,
		           < 0x11 0x0 &gpioa 0x7 0x0 >,
		           < 0x12 0x0 &gpioa 0x6 0x0 >,
		           < 0x13 0x0 &gpioa 0x5 0x0 >,
		           < 0x14 0x0 &gpioa 0xb 0x0 >,
		           < 0x15 0x0 &gpioa 0xc 0x0 >;    /* in zephyr\boards\st\nucleo_wl55jc\arduino_r3_connector.dtsi:15 */
	};

	/* node '/st-morpho-header' defined in zephyr\boards\st\nucleo_wl55jc\st_morpho_connector.dtsi:10 */
	st_morpho_header: st-morpho-header {
		compatible = "st-morpho-header";        /* in zephyr\boards\st\nucleo_wl55jc\st_morpho_connector.dtsi:11 */
		#gpio-cells = < 0x2 >;                  /* in zephyr\boards\st\nucleo_wl55jc\st_morpho_connector.dtsi:12 */
		gpio-map-mask = < 0xff 0x0 >;           /* in zephyr\boards\st\nucleo_wl55jc\st_morpho_connector.dtsi:13 */
		gpio-map-pass-thru = < 0x0 0x7f >;      /* in zephyr\boards\st\nucleo_wl55jc\st_morpho_connector.dtsi:14 */
		gpio-map = < 0x6 0x0 &gpioh 0x3 0x0 >,
		           < 0xc 0x0 &gpioa 0xd 0x0 >,
		           < 0xe 0x0 &gpioa 0xe 0x0 >,
		           < 0x10 0x0 &gpioa 0xf 0x0 >,
		           < 0x16 0x0 &gpioc 0xd 0x0 >,
		           < 0x18 0x0 &gpioc 0xe 0x0 >,
		           < 0x1a 0x0 &gpioc 0xf 0x0 >,
		           < 0x1b 0x0 &gpiob 0x1 0x0 >,
		           < 0x1d 0x0 &gpiob 0x2 0x0 >,
		           < 0x1f 0x0 &gpioa 0xa 0x0 >,
		           < 0x21 0x0 &gpiob 0x4 0x0 >,
		           < 0x23 0x0 &gpiob 0xe 0x0 >,
		           < 0x25 0x0 &gpiob 0xd 0x0 >,
		           < 0x48 0x0 &gpioa 0x0 0x0 >,
		           < 0x49 0x0 &gpioc 0x4 0x0 >,
		           < 0x4a 0x0 &gpioa 0xc 0x0 >,
		           < 0x4b 0x0 &gpioc 0x5 0x0 >,
		           < 0x4c 0x0 &gpioa 0xb 0x0 >,
		           < 0x52 0x0 &gpioa 0x5 0x0 >,
		           < 0x53 0x0 &gpioc 0x6 0x0 >,
		           < 0x54 0x0 &gpioa 0x6 0x0 >,
		           < 0x55 0x0 &gpioc 0x0 0x0 >,
		           < 0x56 0x0 &gpioa 0x7 0x0 >,
		           < 0x57 0x0 &gpioa 0x8 0x0 >,
		           < 0x58 0x0 &gpioa 0x4 0x0 >,
		           < 0x5a 0x0 &gpioa 0x9 0x0 >,
		           < 0x5c 0x0 &gpioc 0x2 0x0 >,
		           < 0x5d 0x0 &gpiob 0x0 0x0 >,
		           < 0x5e 0x0 &gpioc 0x1 0x0 >,
		           < 0x60 0x0 &gpiob 0xa 0x0 >,
		           < 0x61 0x0 &gpiob 0x9 0x0 >,
		           < 0x62 0x0 &gpiob 0x8 0x0 >,
		           < 0x63 0x0 &gpiob 0xf 0x0 >,
		           < 0x64 0x0 &gpiob 0x5 0x0 >,
		           < 0x65 0x0 &gpiob 0xb 0x0 >,
		           < 0x66 0x0 &gpiob 0x3 0x0 >,
		           < 0x68 0x0 &gpiob 0xc 0x0 >,
		           < 0x6a 0x0 &gpiob 0x6 0x0 >,
		           < 0x6b 0x0 &gpioa 0x1 0x0 >,
		           < 0x6c 0x0 &gpiob 0x7 0x0 >,
		           < 0x6d 0x0 &gpioc 0x3 0x0 >; /* in zephyr\boards\st\nucleo_wl55jc\st_morpho_connector.dtsi:15 */
	};

	/* node '/leds' defined in zephyr\boards\st\nucleo_wl55jc\nucleo_wl55jc.dts:27 */
	leds: leds {
		compatible = "gpio-leds"; /* in ..\Downloads\blink_basic\build\zephyr\boards\nucleo_wl55jc.overlay:15 */

		/* node '/leds/led_0' defined in zephyr\boards\st\nucleo_wl55jc\nucleo_wl55jc.dts:31 */
		blue_led_1: led_0 {
			gpios = < &gpiob 0xf 0x0 >; /* in zephyr\boards\st\nucleo_wl55jc\nucleo_wl55jc.dts:32 */
			label = "User LED1";        /* in zephyr\boards\st\nucleo_wl55jc\nucleo_wl55jc.dts:33 */
		};

		/* node '/leds/led_1' defined in zephyr\boards\st\nucleo_wl55jc\nucleo_wl55jc.dts:37 */
		green_led_2: led_1 {
			gpios = < &gpiob 0x9 0x0 >; /* in zephyr\boards\st\nucleo_wl55jc\nucleo_wl55jc.dts:38 */
			label = "User LED2";        /* in zephyr\boards\st\nucleo_wl55jc\nucleo_wl55jc.dts:39 */
		};

		/* node '/leds/led_2' defined in zephyr\boards\st\nucleo_wl55jc\nucleo_wl55jc.dts:43 */
		red_led_3: led_2 {
			gpios = < &gpiob 0xb 0x0 >; /* in zephyr\boards\st\nucleo_wl55jc\nucleo_wl55jc.dts:44 */
			label = "User LED3";        /* in zephyr\boards\st\nucleo_wl55jc\nucleo_wl55jc.dts:45 */
		};

		/* node '/leds/red_led' defined in ..\Downloads\blink_basic\build\zephyr\boards\nucleo_wl55jc.overlay:18 */
		led_r: red_led {
			gpios = < &gpiob 0x5 0x1 >; /* in ..\Downloads\blink_basic\build\zephyr\boards\nucleo_wl55jc.overlay:19 */
			label = "LED Red";          /* in ..\Downloads\blink_basic\build\zephyr\boards\nucleo_wl55jc.overlay:20 */
		};

		/* node '/leds/green_led' defined in ..\Downloads\blink_basic\build\zephyr\boards\nucleo_wl55jc.overlay:22 */
		led_g: green_led {
			gpios = < &gpiob 0x8 0x1 >; /* in ..\Downloads\blink_basic\build\zephyr\boards\nucleo_wl55jc.overlay:23 */
			label = "LED Green";        /* in ..\Downloads\blink_basic\build\zephyr\boards\nucleo_wl55jc.overlay:24 */
		};

		/* node '/leds/blue_led' defined in ..\Downloads\blink_basic\build\zephyr\boards\nucleo_wl55jc.overlay:26 */
		led_b: blue_led {
			gpios = < &gpiob 0xa 0x1 >; /* in ..\Downloads\blink_basic\build\zephyr\boards\nucleo_wl55jc.overlay:27 */
			label = "LED Blue";         /* in ..\Downloads\blink_basic\build\zephyr\boards\nucleo_wl55jc.overlay:28 */
		};

		/* node '/leds/rgb_led_ctrl' defined in ..\Downloads\blink_basic\build\zephyr\boards\nucleo_wl55jc.overlay:30 */
		rgb_led_ctrl: rgb_led_ctrl {
			gpios = < &gpiob 0x3 0x0 >; /* in ..\Downloads\blink_basic\build\zephyr\boards\nucleo_wl55jc.overlay:31 */
			label = "LED TCS";          /* in ..\Downloads\blink_basic\build\zephyr\boards\nucleo_wl55jc.overlay:32 */
		};

		/* node '/leds/soil_gpio_d2' defined in ..\Downloads\blink_basic\build\zephyr\boards\nucleo_wl55jc.overlay:34 */
		soil_gpio_d2: soil_gpio_d2 {
			gpios = < &gpiob 0x4 0x0 >; /* in ..\Downloads\blink_basic\build\zephyr\boards\nucleo_wl55jc.overlay:35 */
			label = "SOIL MOISTURE";    /* in ..\Downloads\blink_basic\build\zephyr\boards\nucleo_wl55jc.overlay:36 */
		};
	};

	/* node '/gpio_keys' defined in zephyr\boards\st\nucleo_wl55jc\nucleo_wl55jc.dts:49 */
	gpio_keys {
		compatible = "gpio-keys"; /* in zephyr\boards\st\nucleo_wl55jc\nucleo_wl55jc.dts:50 */

		/* node '/gpio_keys/button_0' defined in zephyr\boards\st\nucleo_wl55jc\nucleo_wl55jc.dts:53 */
		user_button_1: button_0 {
			label = "SW1";               /* in zephyr\boards\st\nucleo_wl55jc\nucleo_wl55jc.dts:54 */
			gpios = < &gpioa 0x0 0x11 >; /* in zephyr\boards\st\nucleo_wl55jc\nucleo_wl55jc.dts:55 */
			zephyr,code = < 0xb >;       /* in zephyr\boards\st\nucleo_wl55jc\nucleo_wl55jc.dts:56 */
		};

		/* node '/gpio_keys/button_1' defined in zephyr\boards\st\nucleo_wl55jc\nucleo_wl55jc.dts:60 */
		user_button_2: button_1 {
			label = "SW2";               /* in zephyr\boards\st\nucleo_wl55jc\nucleo_wl55jc.dts:61 */
			gpios = < &gpioa 0x1 0x11 >; /* in zephyr\boards\st\nucleo_wl55jc\nucleo_wl55jc.dts:62 */
			zephyr,code = < 0x2 >;       /* in zephyr\boards\st\nucleo_wl55jc\nucleo_wl55jc.dts:63 */
		};

		/* node '/gpio_keys/button_2' defined in zephyr\boards\st\nucleo_wl55jc\nucleo_wl55jc.dts:67 */
		user_button_3: button_2 {
			label = "SW3";               /* in zephyr\boards\st\nucleo_wl55jc\nucleo_wl55jc.dts:68 */
			gpios = < &gpioc 0x6 0x11 >; /* in zephyr\boards\st\nucleo_wl55jc\nucleo_wl55jc.dts:69 */
			zephyr,code = < 0x3 >;       /* in zephyr\boards\st\nucleo_wl55jc\nucleo_wl55jc.dts:70 */
		};
	};
};
